AUTOSAR XML (schema 3.1.2)
package /Components/SWC_TraBVx
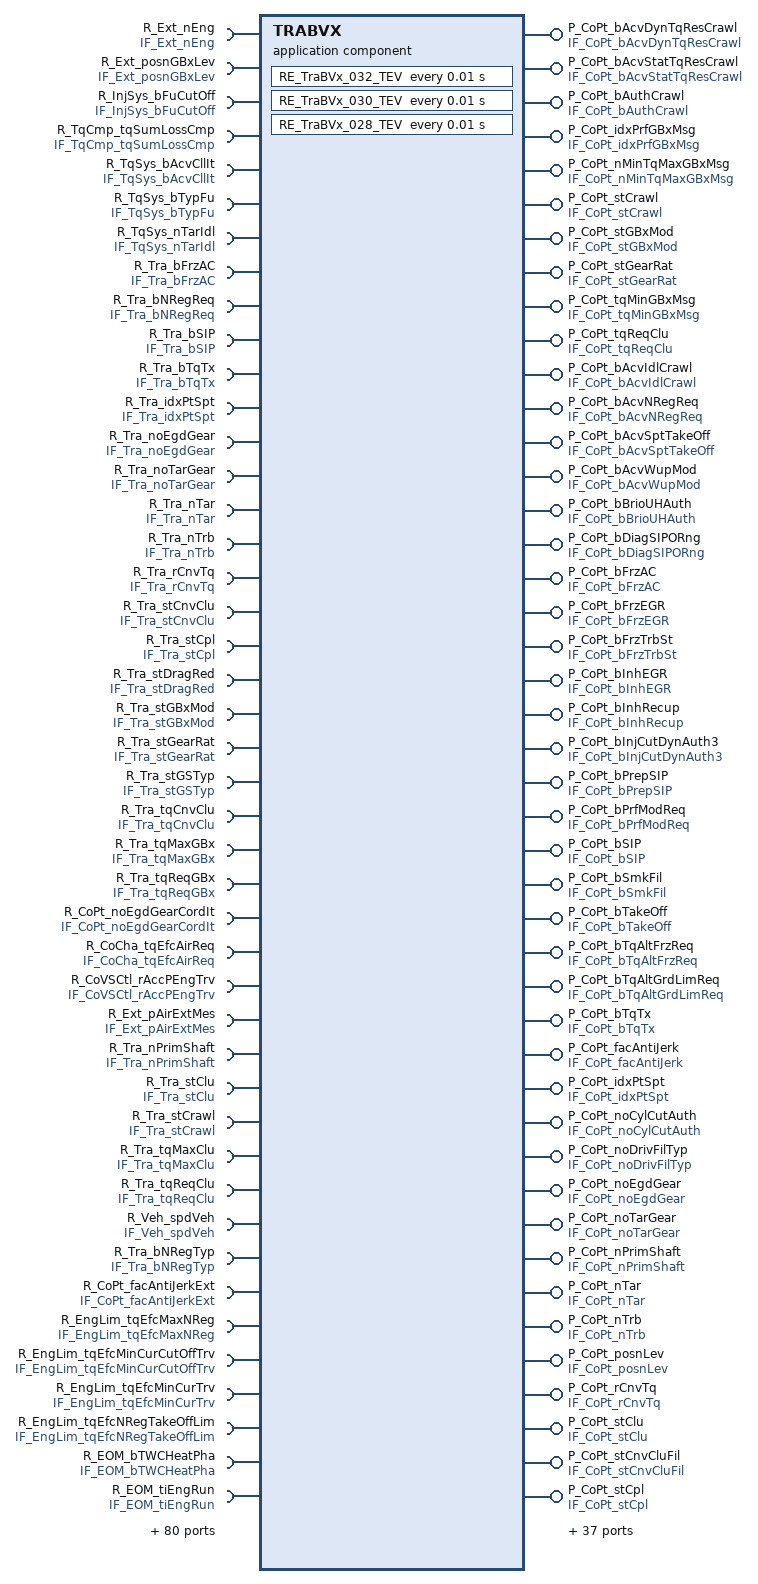
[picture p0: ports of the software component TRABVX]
  application software component type TRABVX
    124 x require port:
      R_Ext_nEng: unqueued-receiver-com-spec{data-element=Ext_nEng, init-value=ConstantValue, resync-time=0}, required-interface=IF_Ext_nEng  # Receiver of interface IF_Ext_nEng - Requirement Reference: [01552_10_01264-TraBVx-I038(0)]
      R_Ext_posnGBxLev: unqueued-receiver-com-spec{data-element=Ext_posnGBxLev, init-value=ConstantValue1, resync-time=0}, required-interface=IF_Ext_posnGBxLev  # Receiver of interface IF_Ext_posnGBxLev - Requirement Reference: [01552_10_01264-TraBVx-I039(0)]
      R_InjSys_bFuCutOff: unqueued-receiver-com-spec{data-element=InjSys_bFuCutOff, init-value=ConstantValue3, resync-time=0}, required-interface=IF_InjSys_bFuCutOff  # Receiver of interface IF_InjSys_bFuCutOff - Requirement Reference: [01552_10_01264-TraBVx-I040(1)]
      R_TqCmp_tqSumLossCmp: unqueued-receiver-com-spec{data-element=TqCmp_tqSumLossCmp, init-value=ConstantValue5, resync-time=0}, required-interface=IF_TqCmp_tqSumLossCmp  # Receiver of interface IF_TqCmp_tqSumLossCmp - Requirement Reference: [01552_10_01264-TraBVx-I041(0)]
      R_TqSys_bAcvCllIt: unqueued-receiver-com-spec{data-element=TqSys_bAcvCllIt, init-value=ConstantValue7, resync-time=0}, required-interface=IF_TqSys_bAcvCllIt  # Receiver of interface IF_TqSys_bAcvCllIt - Requirement Reference: [01552_10_01264-TraBVx-I042(0)]
      R_TqSys_bTypFu: unqueued-receiver-com-spec{data-element=TqSys_bTypFu, init-value=ConstantValue9, resync-time=0}, required-interface=IF_TqSys_bTypFu  # Receiver of interface IF_TqSys_bTypFu - Requirement Reference: [01552_10_01264-TraBVx-I043(0)]
      R_TqSys_nTarIdl: unqueued-receiver-com-spec{data-element=TqSys_nTarIdl, init-value=ConstantValue11, resync-time=0}, required-interface=IF_TqSys_nTarIdl  # Receiver of interface IF_TqSys_nTarIdl - Requirement Reference: [01552_10_01264-TraBVx-I044(0)]
      R_Tra_bFrzAC: unqueued-receiver-com-spec{data-element=Tra_bFrzAC, init-value=Tra_bFrzAC_Cst, resync-time=0}, required-interface=IF_Tra_bFrzAC  # Receiver of interface IF_Tra_bFrzAC - Requirement Reference: [01552_10_01264-TraBVx-I046(0)]
      R_Tra_bNRegReq: unqueued-receiver-com-spec{data-element=Tra_bNRegReq, init-value=Tra_bNRegReq_Cst, resync-time=0}, required-interface=IF_Tra_bNRegReq  # Receiver of interface IF_Tra_bNRegReq - Requirement Reference: [01552_10_01264-TraBVx-I047(0)]
      R_Tra_bSIP: unqueued-receiver-com-spec{data-element=Tra_bSIP, init-value=Tra_bSIP_Cst, resync-time=0}, required-interface=IF_Tra_bSIP  # Receiver of interface IF_Tra_bSIP - Requirement Reference: [01552_10_01264-TraBVx-I049(0)]
      R_Tra_bTqTx: unqueued-receiver-com-spec{data-element=Tra_bTqTx, init-value=Tra_bTqTx_Cst, resync-time=0}, required-interface=IF_Tra_bTqTx  # Receiver of interface IF_Tra_bTqTx - Requirement Reference: [01552_10_01264-TraBVx-I050(1)]
      R_Tra_idxPtSpt: unqueued-receiver-com-spec{data-element=Tra_idxPtSpt, init-value=Tra_idxPtSpt_Cst, resync-time=0}, required-interface=IF_Tra_idxPtSpt  # Receiver of interface IF_Tra_idxPtSpt - Requirement Reference: [01552_10_01264-TraBVx-I051(1)]
      R_Tra_noEgdGear: unqueued-receiver-com-spec{data-element=Tra_noEgdGear, init-value=ConstantValue13, resync-time=0}, required-interface=IF_Tra_noEgdGear  # Receiver of interface IF_Tra_noEgdGear - Requirement Reference: [01552_10_01264-TraBVx-I052(2)]
      R_Tra_noTarGear: unqueued-receiver-com-spec{data-element=Tra_noTarGear, init-value=ConstantValue15, resync-time=0}, required-interface=IF_Tra_noTarGear  # Receiver of interface IF_Tra_noTarGear - Requirement Reference: [01552_10_01264-TraBVx-I053(2)]
      R_Tra_nTar: unqueued-receiver-com-spec{data-element=Tra_nTar, init-value=Tra_nTar_Cst, resync-time=0}, required-interface=IF_Tra_nTar  # Receiver of interface IF_Tra_nTar - Requirement Reference: [01552_10_01264-TraBVx-I054(0)]
      R_Tra_nTrb: unqueued-receiver-com-spec{data-element=Tra_nTrb, init-value=Tra_nTrb_Cst, resync-time=0}, required-interface=IF_Tra_nTrb  # Receiver of interface IF_Tra_nTrb - Requirement Reference: [01552_10_01264-TraBVx-I055(1)]
      R_Tra_rCnvTq: unqueued-receiver-com-spec{data-element=Tra_rCnvTq, init-value=Tra_rCnvTq_Cst, resync-time=0}, required-interface=IF_Tra_rCnvTq  # Receiver of interface IF_Tra_rCnvTq - Requirement Reference: [01552_10_01264-TraBVx-I056(1)]
      R_Tra_stCnvClu: unqueued-receiver-com-spec{data-element=Tra_stCnvClu, init-value=Tra_stCnvClu_Cst, resync-time=0}, required-interface=IF_Tra_stCnvClu  # Receiver of interface IF_Tra_stCnvClu - Requirement Reference: [01552_10_01264-TraBVx-I057(0)]
      R_Tra_stCpl: unqueued-receiver-com-spec{data-element=Tra_stCpl, init-value=Tra_stCpl_Cst, resync-time=0}, required-interface=IF_Tra_stCpl  # Receiver of interface IF_Tra_stCpl - Requirement Reference: [01552_10_01264-TraBVx-I058(1)]
      R_Tra_stDragRed: unqueued-receiver-com-spec{data-element=Tra_stDragRed, init-value=Tra_stDragRed_Cst, resync-time=0}, required-interface=IF_Tra_stDragRed  # Receiver of interface IF_Tra_stDragRed - Requirement Reference: [01552_10_01264-TraBVx-I059(0)]
      R_Tra_stGBxMod: unqueued-receiver-com-spec{data-element=Tra_stGBxMod, init-value=ConstantValue17, resync-time=0}, required-interface=IF_Tra_stGBxMod  # Receiver of interface IF_Tra_stGBxMod - Requirement Reference: [01552_10_01264-TraBVx-I060(1)]
      R_Tra_stGearRat: unqueued-receiver-com-spec{data-element=Tra_stGearRat, init-value=Tra_stGearRat_Cst, resync-time=0}, required-interface=IF_Tra_stGearRat  # Receiver of interface IF_Tra_stGearRat - Requirement Reference: [01552_10_01264-TraBVx-I061(1)]
      R_Tra_stGSTyp: unqueued-receiver-com-spec{data-element=Tra_stGSTyp, init-value=Tra_stGSTyp_Cst, resync-time=0}, required-interface=IF_Tra_stGSTyp  # Receiver of interface IF_Tra_stGSTyp - Requirement Reference: [01552_10_01264-TraBVx-I062(1)]
      R_Tra_tqCnvClu: unqueued-receiver-com-spec{data-element=Tra_tqCnvClu, init-value=Tra_tqCnvClu_Cst, resync-time=0}, required-interface=IF_Tra_tqCnvClu  # Receiver of interface IF_Tra_tqCnvClu - Requirement Reference: [01552_10_01264-TraBVx-I064(0)]
      R_Tra_tqMaxGBx: unqueued-receiver-com-spec{data-element=Tra_tqMaxGBx, init-value=Tra_tqMaxGBx_Cst, resync-time=0}, required-interface=IF_Tra_tqMaxGBx  # Receiver of interface IF_Tra_tqMaxGBx - Requirement Reference: [01552_10_01264-TraBVx-I065(0)]
      R_Tra_tqReqGBx: unqueued-receiver-com-spec{data-element=Tra_tqReqGBx, init-value=Tra_tqReqGBx_Cst, resync-time=0}, required-interface=IF_Tra_tqReqGBx  # Receiver of interface IF_Tra_tqReqGBx - Requirement Reference: [01552_10_01264-TraBVx-I066(0)]
      R_CoPt_noEgdGearCordIt: unqueued-receiver-com-spec{data-element=CoPt_noEgdGearCordIt, init-value=ConstantValue19, resync-time=0}, required-interface=IF_CoPt_noEgdGearCordIt  # Receiver of interface IF_CoPt_noEgdGearCordIt - Requirement Reference: [01552_10_01264-TraBVx-I104(0)]
      R_CoCha_tqEfcAirReq: unqueued-receiver-com-spec{data-element=CoCha_tqEfcAirReq, init-value=ConstantValue21, resync-time=0}, required-interface=IF_CoCha_tqEfcAirReq  # Receiver of interface IF_CoCha_tqEfcAirReq - Requirement Reference: [01552_10_01264-TraBVx-I143(1)]
      R_CoVSCtl_rAccPEngTrv: unqueued-receiver-com-spec{data-element=CoVSCtl_rAccPEngTrv, init-value=ConstantValue23, resync-time=0}, required-interface=IF_CoVSCtl_rAccPEngTrv  # Receiver of interface IF_CoVSCtl_rAccPEngTrv - Requirement Reference: [01552_10_01264-TraBVx-I144(1)]
      R_Ext_pAirExtMes: unqueued-receiver-com-spec{data-element=Ext_pAirExtMes, init-value=ConstantValue25, resync-time=0}, required-interface=IF_Ext_pAirExtMes  # Receiver of interface IF_Ext_pAirExtMes - Requirement Reference: [01552_10_01264-TraBVx-I145(0)]
      R_Tra_nPrimShaft: unqueued-receiver-com-spec{data-element=Tra_nPrimShaft, init-value=Tra_nPrimShaft_Cst, resync-time=0}, required-interface=IF_Tra_nPrimShaft  # Receiver of interface IF_Tra_nPrimShaft - Requirement Reference: [01552_10_01264-TraBVx-I147(0)]
      R_Tra_stClu: unqueued-receiver-com-spec{data-element=Tra_stClu, init-value=Tra_stClu_Cst, resync-time=0}, required-interface=IF_Tra_stClu  # Receiver of interface IF_Tra_stClu - Requirement Reference: [01552_10_01264-TraBVx-I148(0)]
      R_Tra_stCrawl: unqueued-receiver-com-spec{data-element=Tra_stCrawl, init-value=Tra_stCrawl_Cst, resync-time=0}, required-interface=IF_Tra_stCrawl  # Receiver of interface IF_Tra_stCrawl - Requirement Reference: [01552_10_01264-TraBVx-I149(1)]
      R_Tra_tqMaxClu: unqueued-receiver-com-spec{data-element=Tra_tqMaxClu, init-value=Tra_tqMaxClu_Cst, resync-time=0}, required-interface=IF_Tra_tqMaxClu  # Receiver of interface IF_Tra_tqMaxClu - Requirement Reference: [01552_10_01264-TraBVx-I151(0)]
      R_Tra_tqReqClu: unqueued-receiver-com-spec{data-element=Tra_tqReqClu, init-value=Tra_tqReqClu_Cst, resync-time=0}, required-interface=IF_Tra_tqReqClu  # Receiver of interface IF_Tra_tqReqClu - Requirement Reference: [01552_10_01264-TraBVx-I152(1)]
      R_Veh_spdVeh: unqueued-receiver-com-spec{data-element=Veh_spdVeh, init-value=ConstantValue27, resync-time=0}, required-interface=IF_Veh_spdVeh  # Receiver of interface IF_Veh_spdVeh - Requirement Reference: [01552_10_01264-TraBVx-I153(0)]
      R_Tra_bNRegTyp: unqueued-receiver-com-spec{data-element=Tra_bNRegTyp, init-value=Tra_bNRegTyp_Cst, resync-time=0}, required-interface=IF_Tra_bNRegTyp  # Receiver of interface IF_Tra_bNRegTyp - Requirement Reference: [01552_10_01264-TraBVx-I192(1)]
      R_CoPt_facAntiJerkExt: unqueued-receiver-com-spec{data-element=CoPt_facAntiJerkExt, init-value=CoPt_facAntiJerkExt_Cst, resync-time=0}, required-interface=IF_CoPt_facAntiJerkExt  # Receiver of interface IF_CoPt_facAntiJerkExt - Requirement Reference: [01552_10_01264-TraBVx-I287(1)]
      R_EngLim_tqEfcMaxNReg: unqueued-receiver-com-spec{data-element=EngLim_tqEfcMaxNReg, init-value=ConstantValue29, resync-time=0}, required-interface=IF_EngLim_tqEfcMaxNReg  # Receiver of interface IF_EngLim_tqEfcMaxNReg - Requirement Reference: [01552_10_01264-TraBVx-I404(1)]
      R_EngLim_tqEfcMinCurCutOffTrv: unqueued-receiver-com-spec{data-element=EngLim_tqEfcMinCurCutOffTrv, init-value=ConstantValue31, resync-time=0}, required-interface=IF_EngLim_tqEfcMinCurCutOffTrv  # Receiver of interface IF_EngLim_tqEfcMinCurCutOffTrv - Requirement Reference: [01552_10_01264-TraBVx-I405(1)]
      R_EngLim_tqEfcMinCurTrv: unqueued-receiver-com-spec{data-element=EngLim_tqEfcMinCurTrv, init-value=ConstantValue33, resync-time=0}, required-interface=IF_EngLim_tqEfcMinCurTrv  # Receiver of interface IF_EngLim_tqEfcMinCurTrv - Requirement Reference: [01552_10_01264-TraBVx-I406(1)]
      R_EngLim_tqEfcNRegTakeOffLim: unqueued-receiver-com-spec{data-element=EngLim_tqEfcNRegTakeOffLim, init-value=ConstantValue35, resync-time=0}, required-interface=IF_EngLim_tqEfcNRegTakeOffLim  # Receiver of interface IF_EngLim_tqEfcNRegTakeOffLim - Requirement Reference: [01552_10_01264-TraBVx-I407(0)]
      R_EOM_bTWCHeatPha: unqueued-receiver-com-spec{data-element=EOM_bTWCHeatPha, init-value=ConstantValue37, resync-time=0}, required-interface=IF_EOM_bTWCHeatPha  # Receiver of interface IF_EOM_bTWCHeatPha - Requirement Reference: [01552_10_01264-TraBVx-I408(1)]
      R_EOM_tiEngRun: unqueued-receiver-com-spec{data-element=EOM_tiEngRun, init-value=ConstantValue39, resync-time=0}, required-interface=IF_EOM_tiEngRun  # Receiver of interface IF_EOM_tiEngRun - Requirement Reference: [01552_10_01264-TraBVx-I409(0)]
      R_Ext_stGBxCf: unqueued-receiver-com-spec{data-element=Ext_stGBxCf, init-value=ConstantValue41, resync-time=0}, required-interface=IF_Ext_stGBxCf  # Receiver of interface IF_Ext_stGBxCf - Requirement Reference: [01552_10_01264-TraBVx-I410(0)]
      R_Ext_stTraTypCf: unqueued-receiver-com-spec{data-element=Ext_stTraTypCf, init-value=ConstantValue43, resync-time=0}, required-interface=IF_Ext_stTraTypCf  # Receiver of interface IF_Ext_stTraTypCf - Requirement Reference: [01552_10_01264-TraBVx-I411(1)]
      R_Ext_tAir: unqueued-receiver-com-spec{data-element=Ext_tAir, init-value=ConstantValue45, resync-time=0}, required-interface=IF_Ext_tAir  # Receiver of interface IF_Ext_tAir - Requirement Reference: [01552_10_01264-TraBVx-I412(0)]
      R_Ext_tCoMes: unqueued-receiver-com-spec{data-element=Ext_tCoMes, init-value=ConstantValue47, resync-time=0}, required-interface=IF_Ext_tCoMes  # Receiver of interface IF_Ext_tCoMes - Requirement Reference: [01552_10_01264-TraBVx-I413(1)]
      R_TqSys_bAcvOvbReq: unqueued-receiver-com-spec{data-element=TqSys_bAcvOvbReq, init-value=TqSys_bAcvOvbReq_Cst, resync-time=0}, required-interface=IF_TqSys_bAcvOvbReq  # Receiver of interface IF_TqSys_bAcvOvbReq - Requirement Reference: [01552_10_01264-TraBVx-I414(1)]
      R_TqSys_stTypPwtCf: unqueued-receiver-com-spec{data-element=TqSys_stTypPwtCf, init-value=ConstantValue49, resync-time=0}, required-interface=IF_TqSys_stTypPwtCf  # Receiver of interface IF_TqSys_stTypPwtCf - Requirement Reference: [01552_10_01264-TraBVx-I416(0)]
      R_TqSys_tiDeacOvbReq: unqueued-receiver-com-spec{data-element=TqSys_tiDeacOvbReq, init-value=TqSys_tiDeacOvbReq_Cst, resync-time=0}, required-interface=IF_TqSys_tiDeacOvbReq  # Receiver of interface IF_TqSys_tiDeacOvbReq - Requirement Reference: [01552_10_01264-TraBVx-I417(1)]
      R_TqSys_tqEfcIdl: unqueued-receiver-com-spec{data-element=TqSys_tqEfcIdl, init-value=ConstantValue51, resync-time=0}, required-interface=IF_TqSys_tqEfcIdl  # Receiver of interface IF_TqSys_tqEfcIdl - Requirement Reference: [01552_10_01264-TraBVx-I418(1)]
      R_Cha_tqDynASRReq: unqueued-receiver-com-spec{data-element=Cha_tqDynASRReq, init-value=ConstantValue53, resync-time=0}, required-interface=IF_Cha_tqDynASRReq  # Receiver of interface IF_Cha_tqDynASRReq - Requirement Reference: [01552_10_01264-TraBVx-I423(0)]
      R_Cha_tqMSRReq: unqueued-receiver-com-spec{data-element=Cha_tqMSRReq, init-value=ConstantValue55, resync-time=0}, required-interface=IF_Cha_tqMSRReq  # Receiver of interface IF_Cha_tqMSRReq - Requirement Reference: [01552_10_01264-TraBVx-I424(0)]
      R_CoCha_tqEfcReq: unqueued-receiver-com-spec{data-element=CoCha_tqEfcReq, init-value=ConstantValue57, resync-time=0}, required-interface=IF_CoCha_tqEfcReq  # Receiver of interface IF_CoCha_tqEfcReq - Requirement Reference: [01552_10_01264-TraBVx-I425(0)]
      R_CoCha_tqEfcReqExt: unqueued-receiver-com-spec{data-element=CoCha_tqEfcReqExt, init-value=CoCha_tqEfcReqExt_Cst, resync-time=0}, required-interface=IF_CoCha_tqEfcReqExt  # Receiver of interface IF_CoCha_tqEfcReqExt - Requirement Reference: [01552_10_01264-TraBVx-I426(1)]
      R_CoPt_bAcvTqMaxEstim: unqueued-receiver-com-spec{data-element=CoPt_bAcvTqMaxEstim, init-value=CoPt_bAcvTqMaxEstim_Cst, resync-time=0}, required-interface=IF_CoPt_bAcvTqMaxEstim  # Receiver of interface IF_CoPt_bAcvTqMaxEstim - Requirement Reference: [01552_10_01264-TraBVx-I427(1)]
      R_CoPt_bSIP: unqueued-receiver-com-spec{data-element=CoPt_bSIP, init-value=ConstantValue59, resync-time=0}, required-interface=IF_CoPt_bSIP  # Receiver of interface IF_CoPt_bSIP - Requirement Reference: [01552_10_01264-TraBVx-I428(1)]
      R_TqCmp_tqCnvLoss: unqueued-receiver-com-spec{data-element=TqCmp_tqCnvLoss, init-value=ConstantValue61, resync-time=0}, required-interface=IF_TqCmp_tqCnvLoss  # Receiver of interface IF_TqCmp_tqCnvLoss - Requirement Reference: [01552_10_01264-TraBVx-I432(0)]
      R_TqLimEM_tqLimEM: unqueued-receiver-com-spec{data-element=TqLimEM_tqLimEM, init-value=ConstantValue63, resync-time=0}, required-interface=IF_TqLimEM_tqLimEM  # Receiver of interface IF_TqLimEM_tqLimEM - Requirement Reference: [01552_10_01264-TraBVx-I433(0)]
      R_TqLimEM_tqLimEMExt: unqueued-receiver-com-spec{data-element=TqLimEM_tqLimEMExt, init-value=ConstantValue65, resync-time=0}, required-interface=IF_TqLimEM_tqLimEMExt  # Receiver of interface IF_TqLimEM_tqLimEMExt - Requirement Reference: [01552_10_01264-TraBVx-I434(1)]
      R_TqSys_tqCkEfcFil: unqueued-receiver-com-spec{data-element=TqSys_tqCkEfcFil, init-value=ConstantValue67, resync-time=0}, required-interface=IF_TqSys_tqCkEfcFil  # Receiver of interface IF_TqSys_tqCkEfcFil - Requirement Reference: [01552_10_01264-TraBVx-I436(0)]
      R_TqSys_tqCkEfcFilExt: unqueued-receiver-com-spec{data-element=TqSys_tqCkEfcFilExt, init-value=ConstantValue69, resync-time=0}, required-interface=IF_TqSys_tqCkEfcFilExt  # Receiver of interface IF_TqSys_tqCkEfcFilExt - Requirement Reference: [01552_10_01264-TraBVx-I437(1)]
      R_CoPt_bAcvNRegReqBuf: unqueued-receiver-com-spec{data-element=CoPt_bAcvNRegReqBuf, init-value=ConstantValue71, resync-time=0}, required-interface=IF_CoPt_bAcvNRegReqBuf  # Receiver of interface IF_CoPt_bAcvNRegReqBuf - Requirement Reference: [01552_10_01264-TraBVx-I440(0)]
      R_CoPt_noTarGearCordBuf: unqueued-receiver-com-spec{data-element=CoPt_noTarGearCordBuf, init-value=ConstantValue73, resync-time=0}, required-interface=IF_CoPt_noTarGearCordBuf  # Receiver of interface IF_CoPt_noTarGearCordBuf - Requirement Reference: [01552_10_01264-TraBVx-I441(0)]
      R_CoPt_noTarGearCordIt: unqueued-receiver-com-spec{data-element=CoPt_noTarGearCordIt, init-value=ConstantValue75, resync-time=0}, required-interface=IF_CoPt_noTarGearCordIt  # Receiver of interface IF_CoPt_noTarGearCordIt - Requirement Reference: [01552_10_01264-TraBVx-I442(0)]
      R_CoPt_nTar: unqueued-receiver-com-spec{data-element=CoPt_nTar, init-value=ConstantValue77, resync-time=0}, required-interface=IF_CoPt_nTar  # Receiver of interface IF_CoPt_nTar - Requirement Reference: [01552_10_01264-TraBVx-I444(1)]
      R_CoPt_nTarBuf: unqueued-receiver-com-spec{data-element=CoPt_nTarBuf, init-value=ConstantValue79, resync-time=0}, required-interface=IF_CoPt_nTarBuf  # Receiver of interface IF_CoPt_nTarBuf - Requirement Reference: [01552_10_01264-TraBVx-I445(0)]
      R_CoPt_tqIdcAirCordLim_tqGBx: unqueued-receiver-com-spec{data-element=CoPt_tqIdcAirCordLim_tqGBx, init-value=ConstantValue81, resync-time=0}, required-interface=IF_CoPt_tqIdcAirCordLim_tqGBx  # Receiver of interface IF_CoPt_tqIdcAirCordLim_tqGBx - Requirement Reference: [01552_10_01264-TraBVx-I447(1)]
      R_CoPt_tqMaxGBx_nRegBuf: unqueued-receiver-com-spec{data-element=CoPt_tqMaxGBx_nRegBuf, init-value=ConstantValue83, resync-time=0}, required-interface=IF_CoPt_tqMaxGBx_nRegBuf  # Receiver of interface IF_CoPt_tqMaxGBx_nRegBuf - Requirement Reference: [01552_10_01264-TraBVx-I448(0)]
      R_TqEst_tqIdcStrt: unqueued-receiver-com-spec{data-element=TqEst_tqIdcStrt, init-value=TqEst_tqIdcStrt_Cst, resync-time=0}, required-interface=IF_TqEst_tqIdcStrt  # Receiver of interface IF_TqEst_tqIdcStrt - Requirement Reference: [01552_10_01264-TraBVx-I449(0)]
      R_TqSys_bTqSysAcv: unqueued-receiver-com-spec{data-element=TqSys_bTqSysAcv, init-value=ConstantValue85, resync-time=0}, required-interface=IF_TqSys_bTqSysAcv  # Receiver of interface IF_TqSys_bTqSysAcv - Requirement Reference: [01552_10_01264-TraBVx-I450(0)]
      R_TqSys_EveSync_CoPtNReg: unqueued-receiver-com-spec{data-element=TqSys_EveSync_CoPtNReg, init-value=TqSys_EveSync_CoPtNReg_Cst, resync-time=0}, required-interface=IF_TqSys_EveSync_CoPtNReg  # Receiver of interface IF_TqSys_EveSync_CoPtNReg - Requirement Reference: [01552_10_01264-TraBVx-I451(0)]
      R_Cha_stTqReq: unqueued-receiver-com-spec{data-element=Cha_stTqReq, init-value=ConstantValue87, resync-time=0}, required-interface=IF_Cha_stTqReq  # Receiver of interface IF_Cha_stTqReq - Requirement Reference: [01552_10_01264-TraBVx-I457(0)]
      R_CoPt_bSIPBuf: unqueued-receiver-com-spec{data-element=CoPt_bSIPBuf, init-value=ConstantValue89, resync-time=0}, required-interface=IF_CoPt_bSIPBuf  # Receiver of interface IF_CoPt_bSIPBuf - Requirement Reference: [01552_10_01264-TraBVx-I458(0)]
      R_CoPt_tqIdcCordLimBuf_tqGBx: unqueued-receiver-com-spec{data-element=CoPt_tqIdcCordLimBuf_tqGBx, init-value=ConstantValue91, resync-time=0}, required-interface=IF_CoPt_tqIdcCordLimBuf_tqGBx  # Receiver of interface IF_CoPt_tqIdcCordLimBuf_tqGBx - Requirement Reference: [01552_10_01264-TraBVx-I459(0)]
      R_Ext_tiTDC: unqueued-receiver-com-spec{data-element=Ext_tiTDC, init-value=ConstantValue93, resync-time=0}, required-interface=IF_Ext_tiTDC  # Receiver of interface IF_Ext_tiTDC - Requirement Reference: [01552_10_01264-TraBVx-I461(0)]
      R_TqLimEM_tqIdcLimEM: unqueued-receiver-com-spec{data-element=TqLimEM_tqIdcLimEM, init-value=ConstantValue95, resync-time=0}, required-interface=IF_TqLimEM_tqIdcLimEM  # Receiver of interface IF_TqLimEM_tqIdcLimEM - Requirement Reference: [01552_10_01264-TraBVx-I462(1)]
      R_TqSys_bInjCutDynReq: unqueued-receiver-com-spec{data-element=TqSys_bInjCutDynReq, init-value=ConstantValue97, resync-time=0}, required-interface=IF_TqSys_bInjCutDynReq  # Receiver of interface IF_TqSys_bInjCutDynReq - Requirement Reference: [01552_10_01264-TraBVx-I463(0)]
      R_TqSys_EveSync_CoPtNRegCord: unqueued-receiver-com-spec{data-element=TqSys_EveSync_CoPtNRegCord, init-value=TqSys_EveSync_CoPtNRegCord_Cst, resync-time=0}, required-interface=IF_TqSys_EveSync_CoPtNRegCord  # Receiver of interface IF_TqSys_EveSync_CoPtNRegCord - Requirement Reference: [01552_10_01264-TraBVx-I464(0)]
      R_CoPt_bDeacCllBuf: unqueued-receiver-com-spec{data-element=CoPt_bDeacCllBuf, init-value=ConstantValue99, resync-time=0}, required-interface=IF_CoPt_bDeacCllBuf  # Receiver of interface IF_CoPt_bDeacCllBuf - Requirement Reference: [01552_10_01264-TraBVx-I471(0)]
      R_CoPt_bPrepSIP: unqueued-receiver-com-spec{data-element=CoPt_bPrepSIP, init-value=ConstantValue101, resync-time=0}, required-interface=IF_CoPt_bPrepSIP  # Receiver of interface IF_CoPt_bPrepSIP - Requirement Reference: [01552_10_01264-TraBVx-I474(1)]
      R_CoPt_nTrb: unqueued-receiver-com-spec{data-element=CoPt_nTrb, init-value=ConstantValue103, resync-time=0}, required-interface=IF_CoPt_nTrb  # Receiver of interface IF_CoPt_nTrb - Requirement Reference: [01552_10_01264-TraBVx-I475(1)]
      R_CoPt_tqDrvFil: unqueued-receiver-com-spec{data-element=CoPt_tqDrvFil, init-value=CoPt_tqDrvFil_Cst, resync-time=0}, required-interface=IF_CoPt_tqDrvFil  # Receiver of interface IF_CoPt_tqDrvFil - Requirement Reference: [01552_10_01264-TraBVx-I476(1)]
      R_CoPt_tqDrvRaw: unqueued-receiver-com-spec{data-element=CoPt_tqDrvRaw, init-value=CoPt_tqDrvRaw_Cst, resync-time=0}, required-interface=IF_CoPt_tqDrvRaw  # Receiver of interface IF_CoPt_tqDrvRaw - Requirement Reference: [01552_10_01264-TraBVx-I477(1)]
      R_CoPt_tqIdcCord_nRegReq: unqueued-receiver-com-spec{data-element=CoPt_tqIdcCord_nRegReq, init-value=CoPt_tqIdcCord_nRegReq_Cst, resync-time=0}, required-interface=IF_CoPt_tqIdcCord_nRegReq  # Receiver of interface IF_CoPt_tqIdcCord_nRegReq - Requirement Reference: [01552_10_01264-TraBVx-I478(1)]
      R_CoPt_tqIdcMaxGBxBuf: unqueued-receiver-com-spec{data-element=CoPt_tqIdcMaxGBxBuf, init-value=ConstantValue105, resync-time=0}, required-interface=IF_CoPt_tqIdcMaxGBxBuf  # Receiver of interface IF_CoPt_tqIdcMaxGBxBuf - Requirement Reference: [01552_10_01264-TraBVx-I479(0)]
      R_CoPt_tqMaxGBx: unqueued-receiver-com-spec{data-element=CoPt_tqMaxGBx, init-value=ConstantValue107, resync-time=0}, required-interface=IF_CoPt_tqMaxGBx  # Receiver of interface IF_CoPt_tqMaxGBx - Requirement Reference: [01552_10_01264-TraBVx-I480(1)]
      R_TqSys_EveSync_CoPtNCross: unqueued-receiver-com-spec{data-element=TqSys_EveSync_CoPtNCross, init-value=TqSys_EveSync_CoPtNCross_Cst, resync-time=0}, required-interface=IF_TqSys_EveSync_CoPtNCross  # Receiver of interface IF_TqSys_EveSync_CoPtNCross - Requirement Reference: [01552_10_01264-TraBVx-I481(0)]
      R_TqSys_idxTqAccu: unqueued-receiver-com-spec{data-element=TqSys_idxTqAccu, init-value=ConstantValue109, resync-time=0}, required-interface=IF_TqSys_idxTqAccu  # Receiver of interface IF_TqSys_idxTqAccu - Requirement Reference: [01552_10_01264-TraBVx-I482(0)]
      R_TreatTDC_nCkGrd: unqueued-receiver-com-spec{data-element=TreatTDC_nCkGrd, init-value=ConstantValue111, resync-time=0}, required-interface=IF_TreatTDC_nCkGrd  # Receiver of interface IF_TreatTDC_nCkGrd - Requirement Reference: [01552_10_01264-TraBVx-I483(0)]
      R_CoCha_tqEfcAirReqExt: unqueued-receiver-com-spec{data-element=CoCha_tqEfcAirReqExt, init-value=CoCha_tqEfcAirReqExt_Cst, resync-time=0}, required-interface=IF_CoCha_tqEfcAirReqExt  # Receiver of interface IF_CoCha_tqEfcAirReqExt - Requirement Reference: [01552_10_01264-TraBVx-I486(1)]
      R_TqCha_tqAirTqDecReq: unqueued-receiver-com-spec{data-element=TqCha_tqAirTqDecReq, init-value=ConstantValue113, resync-time=0}, required-interface=IF_TqCha_tqAirTqDecReq  # Receiver of interface IF_TqCha_tqAirTqDecReq - Requirement Reference: [01552_10_01264-TraBVx-I488(1)]
      R_TqCha_tqAirTqDecReqExt: unqueued-receiver-com-spec{data-element=TqCha_tqAirTqDecReqExt, init-value=TqCha_tqAirTqDecReqExt_Cst, resync-time=0}, required-interface=IF_TqCha_tqAirTqDecReqExt  # Receiver of interface IF_TqCha_tqAirTqDecReqExt - Requirement Reference: [01552_10_01264-TraBVx-I489(1)]
      R_TqCha_tqAirTqIncReq: unqueued-receiver-com-spec{data-element=TqCha_tqAirTqIncReq, init-value=ConstantValue115, resync-time=0}, required-interface=IF_TqCha_tqAirTqIncReq  # Receiver of interface IF_TqCha_tqAirTqIncReq - Requirement Reference: [01552_10_01264-TraBVx-I490(1)]
      R_TqCha_tqAirTqIncReqExt: unqueued-receiver-com-spec{data-element=TqCha_tqAirTqIncReqExt, init-value=TqCha_tqAirTqIncReqExt_Cst, resync-time=0}, required-interface=IF_TqCha_tqAirTqIncReqExt  # Receiver of interface IF_TqCha_tqAirTqIncReqExt - Requirement Reference: [01552_10_01264-TraBVx-I491(1)]
      R_TqSys_tqCkEfcAirFil: unqueued-receiver-com-spec{data-element=TqSys_tqCkEfcAirFil, init-value=ConstantValue117, resync-time=0}, required-interface=IF_TqSys_tqCkEfcAirFil  # Receiver of interface IF_TqSys_tqCkEfcAirFil - Requirement Reference: [01552_10_01264-TraBVx-I493(1)]
      R_TqSys_tqCkEfcAirFilExt: unqueued-receiver-com-spec{data-element=TqSys_tqCkEfcAirFilExt, init-value=TqSys_tqCkEfcAirFilExt_Cst, resync-time=0}, required-interface=IF_TqSys_tqCkEfcAirFilExt  # Receiver of interface IF_TqSys_tqCkEfcAirFilExt - Requirement Reference: [01552_10_01264-TraBVx-I494(1)]
      R_TqSys_tqEfcAirIdl: unqueued-receiver-com-spec{data-element=TqSys_tqEfcAirIdl, init-value=ConstantValue119, resync-time=0}, required-interface=IF_TqSys_tqEfcAirIdl  # Receiver of interface IF_TqSys_tqEfcAirIdl - Requirement Reference: [01552_10_01264-TraBVx-I495(1)]
      R_CoPt_bAcvNRegReq: unqueued-receiver-com-spec{data-element=CoPt_bAcvNRegReq, init-value=ConstantValue121, resync-time=0}, required-interface=IF_CoPt_bAcvNRegReq  # Receiver of interface IF_CoPt_bAcvNRegReq - Requirement Reference: [01552_10_01264-TraBVx-I497(1)]
      R_CoPt_bAcvNCross: unqueued-receiver-com-spec{data-element=CoPt_bAcvNCross, init-value=CoPt_bAcvNCross_Cst, resync-time=0}, required-interface=IF_CoPt_bAcvNCross  # Receiver of interface IF_CoPt_bAcvNCross - Requirement Reference: [01552_10_01264-TraBVx-I501(1)]
      R_CoPt_tqIdcAirMaxGBx: unqueued-receiver-com-spec{data-element=CoPt_tqIdcAirMaxGBx, init-value=ConstantValue123, resync-time=0}, required-interface=IF_CoPt_tqIdcAirMaxGBx  # Receiver of interface IF_CoPt_tqIdcAirMaxGBx - Requirement Reference: [01552_10_01264-TraBVx-I503(1)]
      R_CoPtUH_bRStrtTypAT: unqueued-receiver-com-spec{data-element=CoPtUH_bRStrtTypAT, init-value=ConstantValue125, resync-time=0}, required-interface=IF_CoPtUH_bRStrtTypAT  # Receiver of interface IF_CoPtUH_bRStrtTypAT - Requirement Reference: [01552_10_01264-TraBVx-I504(0)]
      R_Tra_bSIPPrep: unqueued-receiver-com-spec{data-element=Tra_bSIPPrep, init-value=Tra_bSIPPrep_Cst, resync-time=0}, required-interface=IF_Tra_bSIPPrep  # Receiver of interface IF_Tra_bSIPPrep - Requirement Reference: [01552_10_01264-TraBVx-I505(0)]
      R_Tra_stPhaGearShift: unqueued-receiver-com-spec{data-element=Tra_stPhaGearShift, init-value=Tra_stPhaGearShift_Cst, resync-time=0}, required-interface=IF_Tra_stPhaGearShift  # Receiver of interface IF_Tra_stPhaGearShift - Requirement Reference: [01552_10_01264-TraBVx-I506(0)]
      R_TqSys_stStrtEngTyp: unqueued-receiver-com-spec{data-element=TqSys_stStrtEngTyp, init-value=TqSys_stStrtEngTyp_Cst, resync-time=0}, required-interface=IF_TqSys_stStrtEngTyp  # Receiver of interface IF_TqSys_stStrtEngTyp - Requirement Reference: [01552_10_01264-TraBVx-I507(0)]
      R_Ext_tOilGBx: unqueued-receiver-com-spec{data-element=Ext_tOilGBx, init-value=ConstantValue127, resync-time=0}, required-interface=IF_Ext_tOilGBx  # Receiver of interface IF_Ext_tOilGBx - Requirement Reference: [01552_10_01264-TraBVx-I508(1)]
      R_Tra_bVoltAltBoostReqGBx: unqueued-receiver-com-spec{data-element=Tra_bVoltAltBoostReqGBx, init-value=Tra_bVoltAltBoostReqGBx_Cst, resync-time=0}, required-interface=IF_Tra_bVoltAltBoostReqGBx  # Receiver of interface IF_Tra_bVoltAltBoostReqGBx - Requirement Reference: [01552_10_01264-TraBVx-I678(0)]
      R_Ext_dstVehTotMes: unqueued-receiver-com-spec{data-element=Ext_dstVehTotMes, init-value=ConstantValue129, resync-time=0}, required-interface=IF_Ext_dstVehTotMes  # Receiver of interface IF_Ext_dstVehTotMes - Requirement Reference: [01552_10_01264-TraBVx-I679(0)]
      R_CoPt_bAcvTqNCordBuf: unqueued-receiver-com-spec{data-element=CoPt_bAcvTqNCordBuf, init-value=CoPt_bAcvTqNCordBuf_Cst, resync-time=0}, required-interface=IF_CoPt_bAcvTqNCordBuf  # Receiver of interface IF_CoPt_bAcvTqNCordBuf - Requirement Reference: [01552_10_01264-TraBVx-I680(0)]
      R_CoVSCtl_tqIdcSIPTar: unqueued-receiver-com-spec{data-element=CoVSCtl_tqIdcSIPTar, init-value=CoVSCtl_tqIdcSIPTar_Cst, resync-time=0}, required-interface=IF_CoVSCtl_tqIdcSIPTar  # Receiver of interface IF_CoVSCtl_tqIdcSIPTar - Requirement Reference: [01552_10_01264-TraBVx-I681(0)]
      R_CoVSCtl_tqSIPTar: unqueued-receiver-com-spec{data-element=CoVSCtl_tqSIPTar, init-value=CoVSCtl_tqSIPTar_Cst, resync-time=0}, required-interface=IF_CoVSCtl_tqSIPTar  # Receiver of interface IF_CoVSCtl_tqSIPTar - Requirement Reference: [01552_10_01264-TraBVx-I683(0)]
      R_CoPt_bAcvTqNCord: unqueued-receiver-com-spec{data-element=CoPt_bAcvTqNCord, init-value=CoPt_bAcvTqNCord_Cst, resync-time=0}, required-interface=IF_CoPt_bAcvTqNCord  # Receiver of interface IF_CoPt_bAcvTqNCord - Requirement Reference: [01552_10_01264-TraBVx-I684(0)]
      R_Tra_bEngCrawlAuth: unqueued-receiver-com-spec{data-element=Tra_bEngCrawlAuth, init-value=Tra_bEngCrawlAuth_Cst, resync-time=0}, required-interface=IF_Tra_bEngCrawlAuth  # Receiver of interface IF_Tra_bEngCrawlAuth - Requirement Reference: [01552_10_01264-TraBVx-I685(0)]
      R_Tra_bSpdVehLoDet: unqueued-receiver-com-spec{data-element=Tra_bSpdVehLoDet, init-value=Tra_bSpdVehLoDet_Cst, resync-time=0}, required-interface=IF_Tra_bSpdVehLoDet  # Receiver of interface IF_Tra_bSpdVehLoDet - Requirement Reference: [01552_10_01264-TraBVx-I686(0)]
      R_Tra_stVehDirEstim: unqueued-receiver-com-spec{data-element=Tra_stVehDirEstim, init-value=Tra_stVehDirEstim_Cst, resync-time=0}, required-interface=IF_Tra_stVehDirEstim  # Receiver of interface IF_Tra_stVehDirEstim - Requirement Reference: [01552_10_01264-TraBVx-I687(0)]
      R_CoPt_tqFfNRegBuf: unqueued-receiver-com-spec{data-element=CoPt_tqFfNRegBuf, init-value=CoPt_tqFfNRegBuf_Cst, resync-time=0}, required-interface=IF_CoPt_tqFfNRegBuf  # Receiver of interface IF_CoPt_tqFfNRegBuf - Requirement Reference: [01552_10_01264-TraBVx-I688(0)]
      R_Tra_bInhAC: unqueued-receiver-com-spec{data-element=Tra_bInhAC, init-value=Tra_bInhAC_Cst, resync-time=0}, required-interface=IF_Tra_bInhAC  # Receiver of interface IF_Tra_bInhAC - Requirement Reference: [01552_10_01264-TraBVx-I691(0)]
      R_EngLim_tqCkEfcATLimCordEL2: unqueued-receiver-com-spec{data-element=EngLim_tqCkEfcATLimCordEL2, init-value=EngLim_tqCkEfcATLimCordEL2_Cst, resync-time=0}, required-interface=IF_EngLim_tqCkEfcATLimCordEL2  # Receiver of interface IF_EngLim_tqCkEfcATLimCordEL2 - Requirement Reference: [01552_10_01264-TraBVx-I696(0)]
      R_EngLim_tqCkEfcGBxLimCordEL2: unqueued-receiver-com-spec{data-element=EngLim_tqCkEfcGBxLimCordEL2, init-value=EngLim_tqCkEfcGBxLimCordEL2_Cst, resync-time=0}, required-interface=IF_EngLim_tqCkEfcGBxLimCordEL2  # Receiver of interface IF_EngLim_tqCkEfcGBxLimCordEL2 - Requirement Reference: [01552_10_01264-TraBVx-I697(0)]
      R_EcuM_CurrentMode: required-interface=EcuM_CurrentMode
      R_UCE_stWkuMainRelSt: required-interface=IF_UCE_stWkuMainRelSt
      R_FRM_bInhCoPtSIP: required-interface=FunctionInhibition  # 01552_10_01264-TraBVx-I507(0)
      R_FRM_bInhCoPtCrawl: required-interface=FunctionInhibition  # 01552_10_01264-TraBVx-I508(0)
    81 x provide port:
      P_CoPt_bAcvDynTqResCrawl: unqueued-sender-com-spec{data-element=CoPt_bAcvDynTqResCrawl, can-invalidate=false, init-value=CoPt_bAcvDynTqResCrawl_Cst}, provided-interface=IF_CoPt_bAcvDynTqResCrawl
      P_CoPt_bAcvStatTqResCrawl: unqueued-sender-com-spec{data-element=CoPt_bAcvStatTqResCrawl, can-invalidate=false, init-value=CoPt_bAcvStatTqResCrawl_Cst}, provided-interface=IF_CoPt_bAcvStatTqResCrawl
      P_CoPt_bAuthCrawl: unqueued-sender-com-spec{data-element=CoPt_bAuthCrawl, can-invalidate=false, init-value=CoPt_bAuthCrawl_Cst}, provided-interface=IF_CoPt_bAuthCrawl
      P_CoPt_idxPrfGBxMsg: unqueued-sender-com-spec{data-element=CoPt_idxPrfGBxMsg, can-invalidate=false, init-value=CoPt_idxPrfGBxMsg_Cst}, provided-interface=IF_CoPt_idxPrfGBxMsg
      P_CoPt_nMinTqMaxGBxMsg: unqueued-sender-com-spec{data-element=CoPt_nMinTqMaxGBxMsg, can-invalidate=false, init-value=CoPt_nMinTqMaxGBxMsg_Cst}, provided-interface=IF_CoPt_nMinTqMaxGBxMsg
      P_CoPt_stCrawl: unqueued-sender-com-spec{data-element=CoPt_stCrawl, can-invalidate=false, init-value=CoPt_stCrawl_Cst}, provided-interface=IF_CoPt_stCrawl
      P_CoPt_stGBxMod: unqueued-sender-com-spec{data-element=CoPt_stGBxMod, can-invalidate=false, init-value=CoPt_stGBxMod_Cst}, provided-interface=IF_CoPt_stGBxMod
      P_CoPt_stGearRat: unqueued-sender-com-spec{data-element=CoPt_stGearRat, can-invalidate=false, init-value=CoPt_stGearRat_Cst}, provided-interface=IF_CoPt_stGearRat
      P_CoPt_tqMinGBxMsg: unqueued-sender-com-spec{data-element=CoPt_tqMinGBxMsg, can-invalidate=false, init-value=CoPt_tqMinGBxMsg_Cst}, provided-interface=IF_CoPt_tqMinGBxMsg
      P_CoPt_tqReqClu: unqueued-sender-com-spec{data-element=CoPt_tqReqClu, can-invalidate=false, init-value=CoPt_tqReqClu_Cst}, provided-interface=IF_CoPt_tqReqClu
      P_CoPt_bAcvIdlCrawl: unqueued-sender-com-spec{data-element=CoPt_bAcvIdlCrawl, can-invalidate=false, init-value=CoPt_bAcvIdlCrawl_Cst}, provided-interface=IF_CoPt_bAcvIdlCrawl
      P_CoPt_bAcvNRegReq: unqueued-sender-com-spec{data-element=CoPt_bAcvNRegReq, can-invalidate=false, init-value=ConstantValue131}, provided-interface=IF_CoPt_bAcvNRegReq
      P_CoPt_bAcvSptTakeOff: unqueued-sender-com-spec{data-element=CoPt_bAcvSptTakeOff, can-invalidate=false, init-value=CoPt_bAcvSptTakeOff_Cst}, provided-interface=IF_CoPt_bAcvSptTakeOff
      P_CoPt_bAcvWupMod: unqueued-sender-com-spec{data-element=CoPt_bAcvWupMod, can-invalidate=false, init-value=CoPt_bAcvWupMod_Cst}, provided-interface=IF_CoPt_bAcvWupMod
      P_CoPt_bBrioUHAuth: unqueued-sender-com-spec{data-element=CoPt_bBrioUHAuth, can-invalidate=false, init-value=ConstantValue133}, provided-interface=IF_CoPt_bBrioUHAuth
      P_CoPt_bDiagSIPORng: unqueued-sender-com-spec{data-element=CoPt_bDiagSIPORng, can-invalidate=false, init-value=CoPt_bDiagSIPORng_Cst}, provided-interface=IF_CoPt_bDiagSIPORng
      P_CoPt_bFrzAC: unqueued-sender-com-spec{data-element=CoPt_bFrzAC, can-invalidate=false, init-value=ConstantValue135}, provided-interface=IF_CoPt_bFrzAC
      P_CoPt_bFrzEGR: unqueued-sender-com-spec{data-element=CoPt_bFrzEGR, can-invalidate=false, init-value=CoPt_bFrzEGR_Cst}, provided-interface=IF_CoPt_bFrzEGR
      P_CoPt_bFrzTrbSt: unqueued-sender-com-spec{data-element=CoPt_bFrzTrbSt, can-invalidate=false, init-value=CoPt_bFrzTrbSt_Cst}, provided-interface=IF_CoPt_bFrzTrbSt
      P_CoPt_bInhEGR: unqueued-sender-com-spec{data-element=CoPt_bInhEGR, can-invalidate=false, init-value=ConstantValue137}, provided-interface=IF_CoPt_bInhEGR
      P_CoPt_bInhRecup: unqueued-sender-com-spec{data-element=CoPt_bInhRecup, can-invalidate=false, init-value=ConstantValue139}, provided-interface=IF_CoPt_bInhRecup
      P_CoPt_bInjCutDynAuth3: unqueued-sender-com-spec{data-element=CoPt_bInjCutDynAuth3, can-invalidate=false, init-value=ConstantValue141}, provided-interface=IF_CoPt_bInjCutDynAuth3
      P_CoPt_bPrepSIP: unqueued-sender-com-spec{data-element=CoPt_bPrepSIP, can-invalidate=false, init-value=ConstantValue143}, provided-interface=IF_CoPt_bPrepSIP
      P_CoPt_bPrfModReq: unqueued-sender-com-spec{data-element=CoPt_bPrfModReq, can-invalidate=false, init-value=ConstantValue145}, provided-interface=IF_CoPt_bPrfModReq
      P_CoPt_bSIP: unqueued-sender-com-spec{data-element=CoPt_bSIP, can-invalidate=false, init-value=ConstantValue147}, provided-interface=IF_CoPt_bSIP
      P_CoPt_bSmkFil: unqueued-sender-com-spec{data-element=CoPt_bSmkFil, can-invalidate=false, init-value=CoPt_bSmkFil_Cst}, provided-interface=IF_CoPt_bSmkFil
      P_CoPt_bTakeOff: unqueued-sender-com-spec{data-element=CoPt_bTakeOff, can-invalidate=false, init-value=ConstantValue149}, provided-interface=IF_CoPt_bTakeOff
      P_CoPt_bTqAltFrzReq: unqueued-sender-com-spec{data-element=CoPt_bTqAltFrzReq, can-invalidate=false, init-value=ConstantValue151}, provided-interface=IF_CoPt_bTqAltFrzReq
      P_CoPt_bTqAltGrdLimReq: unqueued-sender-com-spec{data-element=CoPt_bTqAltGrdLimReq, can-invalidate=false, init-value=ConstantValue153}, provided-interface=IF_CoPt_bTqAltGrdLimReq
      P_CoPt_bTqTx: unqueued-sender-com-spec{data-element=CoPt_bTqTx, can-invalidate=false, init-value=ConstantValue155}, provided-interface=IF_CoPt_bTqTx
      P_CoPt_facAntiJerk: unqueued-sender-com-spec{data-element=CoPt_facAntiJerk, can-invalidate=false, init-value=ConstantValue157}, provided-interface=IF_CoPt_facAntiJerk
      P_CoPt_idxPtSpt: unqueued-sender-com-spec{data-element=CoPt_idxPtSpt, can-invalidate=false, init-value=ConstantValue159}, provided-interface=IF_CoPt_idxPtSpt
      P_CoPt_noCylCutAuth: unqueued-sender-com-spec{data-element=CoPt_noCylCutAuth, can-invalidate=false, init-value=ConstantValue161}, provided-interface=IF_CoPt_noCylCutAuth
      P_CoPt_noDrivFilTyp: unqueued-sender-com-spec{data-element=CoPt_noDrivFilTyp, can-invalidate=false, init-value=ConstantValue163}, provided-interface=IF_CoPt_noDrivFilTyp
      P_CoPt_noEgdGear: unqueued-sender-com-spec{data-element=CoPt_noEgdGear, can-invalidate=false, init-value=ConstantValue165}, provided-interface=IF_CoPt_noEgdGear
      P_CoPt_noTarGear: unqueued-sender-com-spec{data-element=CoPt_noTarGear, can-invalidate=false, init-value=ConstantValue167}, provided-interface=IF_CoPt_noTarGear
      P_CoPt_nPrimShaft: unqueued-sender-com-spec{data-element=CoPt_nPrimShaft, can-invalidate=false, init-value=ConstantValue169}, provided-interface=IF_CoPt_nPrimShaft
      P_CoPt_nTar: unqueued-sender-com-spec{data-element=CoPt_nTar, can-invalidate=false, init-value=ConstantValue171}, provided-interface=IF_CoPt_nTar
      P_CoPt_nTrb: unqueued-sender-com-spec{data-element=CoPt_nTrb, can-invalidate=false, init-value=ConstantValue173}, provided-interface=IF_CoPt_nTrb
      P_CoPt_posnLev: unqueued-sender-com-spec{data-element=CoPt_posnLev, can-invalidate=false, init-value=ConstantValue175}, provided-interface=IF_CoPt_posnLev
      P_CoPt_rCnvTq: unqueued-sender-com-spec{data-element=CoPt_rCnvTq, can-invalidate=false, init-value=CoPt_rCnvTq_Cst}, provided-interface=IF_CoPt_rCnvTq
      P_CoPt_stClu: unqueued-sender-com-spec{data-element=CoPt_stClu, can-invalidate=false, init-value=ConstantValue177}, provided-interface=IF_CoPt_stClu
      P_CoPt_stCnvCluFil: unqueued-sender-com-spec{data-element=CoPt_stCnvCluFil, can-invalidate=false, init-value=ConstantValue179}, provided-interface=IF_CoPt_stCnvCluFil
      P_CoPt_stCpl: unqueued-sender-com-spec{data-element=CoPt_stCpl, can-invalidate=false, init-value=ConstantValue181}, provided-interface=IF_CoPt_stCpl
      P_CoPt_stDragRed: unqueued-sender-com-spec{data-element=CoPt_stDragRed, can-invalidate=false, init-value=ConstantValue183}, provided-interface=IF_CoPt_stDragRed
      P_CoPt_stDrvTra: unqueued-sender-com-spec{data-element=CoPt_stDrvTra, can-invalidate=false, init-value=ConstantValue185}, provided-interface=IF_CoPt_stDrvTra
      P_CoPt_stGSTyp: unqueued-sender-com-spec{data-element=CoPt_stGSTyp, can-invalidate=false, init-value=ConstantValue187}, provided-interface=IF_CoPt_stGSTyp
      P_CoPt_tiDeacPrfMod: unqueued-sender-com-spec{data-element=CoPt_tiDeacPrfMod, can-invalidate=false, init-value=ConstantValue189}, provided-interface=IF_CoPt_tiDeacPrfMod
      P_CoPt_tOilGBx: unqueued-sender-com-spec{data-element=CoPt_tOilGBx, can-invalidate=false, init-value=ConstantValue191}, provided-interface=IF_CoPt_tOilGBx
      P_CoPt_tqAirMaxGBx: unqueued-sender-com-spec{data-element=CoPt_tqAirMaxGBx, can-invalidate=false, init-value=ConstantValue193}, provided-interface=IF_CoPt_tqAirMaxGBx
      P_CoPt_tqCnvClu: unqueued-sender-com-spec{data-element=CoPt_tqCnvClu, can-invalidate=false, init-value=ConstantValue195}, provided-interface=IF_CoPt_tqCnvClu
      P_CoPt_tqMaxClu: unqueued-sender-com-spec{data-element=CoPt_tqMaxClu, can-invalidate=false, init-value=ConstantValue197}, provided-interface=IF_CoPt_tqMaxClu
      P_CoPt_tqMaxGBx: unqueued-sender-com-spec{data-element=CoPt_tqMaxGBx, can-invalidate=false, init-value=ConstantValue199}, provided-interface=IF_CoPt_tqMaxGBx
      P_CoPt_tqMaxGBx_nReg: unqueued-sender-com-spec{data-element=CoPt_tqMaxGBx_nReg, can-invalidate=false, init-value=ConstantValue201}, provided-interface=IF_CoPt_tqMaxGBx_nReg
      P_CoPt_tqMaxGBxAir: unqueued-sender-com-spec{data-element=CoPt_tqMaxGBxAir, can-invalidate=false, init-value=CoPt_tqMaxGBxAir_Cst}, provided-interface=IF_CoPt_tqMaxGBxAir
      P_CoPt_bDeacCllIt: unqueued-sender-com-spec{data-element=CoPt_bDeacCllIt, can-invalidate=false, init-value=ConstantValue203}, provided-interface=IF_CoPt_bDeacCllIt
      P_CoPt_tqCord_tqGBx: unqueued-sender-com-spec{data-element=CoPt_tqCord_tqGBx, can-invalidate=false, init-value=ConstantValue205}, provided-interface=IF_CoPt_tqCord_tqGBx
      P_CoPt_tqDrvFil: unqueued-sender-com-spec{data-element=CoPt_tqDrvFil, can-invalidate=false, init-value=CoPt_tqDrvFil_Cst}, provided-interface=IF_CoPt_tqDrvFil
      P_CoPt_tqDrvRaw: unqueued-sender-com-spec{data-element=CoPt_tqDrvRaw, can-invalidate=false, init-value=CoPt_tqDrvRaw_Cst}, provided-interface=IF_CoPt_tqDrvRaw
      P_CoPt_tqIdcAirDslCord_nReg: unqueued-sender-com-spec{data-element=CoPt_tqIdcAirDslCord_nReg, can-invalidate=false, init-value=ConstantValue207}, provided-interface=IF_CoPt_tqIdcAirDslCord_nReg
      P_CoPt_tqIdcCord_nRegReq: unqueued-sender-com-spec{data-element=CoPt_tqIdcCord_nRegReq, can-invalidate=false, init-value=CoPt_tqIdcCord_nRegReq_Cst}, provided-interface=IF_CoPt_tqIdcCord_nRegReq
      P_CoPt_bAcvCll: unqueued-sender-com-spec{data-element=CoPt_bAcvCll, can-invalidate=false, init-value=ConstantValue209}, provided-interface=IF_CoPt_bAcvCll
      P_CoPt_bAcvNCross: unqueued-sender-com-spec{data-element=CoPt_bAcvNCross, can-invalidate=false, init-value=CoPt_bAcvNCross_Cst}, provided-interface=IF_CoPt_bAcvNCross
      P_CoPt_bTqAltFrzReq_nCross: unqueued-sender-com-spec{data-element=CoPt_bTqAltFrzReq_nCross, can-invalidate=false, init-value=ConstantValue211}, provided-interface=IF_CoPt_bTqAltFrzReq_nCross
      P_CoPt_tiTranCll: unqueued-sender-com-spec{data-element=CoPt_tiTranCll, can-invalidate=false, init-value=ConstantValue213}, provided-interface=IF_CoPt_tiTranCll
      P_CoPt_tqIdcReqCord_nRegReq: unqueued-sender-com-spec{data-element=CoPt_tqIdcReqCord_nRegReq, can-invalidate=false, init-value=ConstantValue215}, provided-interface=IF_CoPt_tqIdcReqCord_nRegReq
      P_CoPt_tqIncCll: unqueued-sender-com-spec{data-element=CoPt_tqIncCll, can-invalidate=false, init-value=ConstantValue217}, provided-interface=IF_CoPt_tqIncCll
      P_CoPt_tqAirDrvFil: unqueued-sender-com-spec{data-element=CoPt_tqAirDrvFil, can-invalidate=false, init-value=CoPt_tqAirDrvFil_Cst}, provided-interface=IF_CoPt_tqAirDrvFil
      P_CoPt_tqAirCord_tqGBx: unqueued-sender-com-spec{data-element=CoPt_tqAirCord_tqGBx, can-invalidate=false, init-value=ConstantValue219}, provided-interface=IF_CoPt_tqAirCord_tqGBx
      P_CoPt_tqIdcAirGslCord_nReg: unqueued-sender-com-spec{data-element=CoPt_tqIdcAirGslCord_nReg, can-invalidate=false, init-value=CoPt_tqIdcAirGslCord_nReg_Cst}, provided-interface=IF_CoPt_tqIdcAirGslCord_nReg
      P_CoPt_tqIdcAirCord_nCross: unqueued-sender-com-spec{data-element=CoPt_tqIdcAirCord_nCross, can-invalidate=false, init-value=ConstantValue221}, provided-interface=IF_CoPt_tqIdcAirCord_nCross
      P_CoPt_stVoltAltBoostReq: unqueued-sender-com-spec{data-element=CoPt_stVoltAltBoostReq, can-invalidate=false, init-value=ConstantValue223}, provided-interface=IF_CoPt_stVoltAltBoostReq
      P_CoPt_nPrimShaftTar: unqueued-sender-com-spec{data-element=CoPt_nPrimShaftTar, can-invalidate=false, init-value=CoPt_nPrimShaftTar_Cst}, provided-interface=IF_CoPt_nPrimShaftTar
      P_CoPt_tqFfNReg: unqueued-sender-com-spec{data-element=CoPt_tqFfNReg, can-invalidate=false, init-value=CoPt_tqFfNReg_Cst}, provided-interface=IF_CoPt_tqFfNReg
      P_CoPt_bEngCrawlAuth: unqueued-sender-com-spec{data-element=CoPt_bEngCrawlAuth, can-invalidate=false, init-value=CoPt_bEngCrawlAuth_Cst}, provided-interface=IF_CoPt_bEngCrawlAuth
      P_CoPt_stVehDirEstim: unqueued-sender-com-spec{data-element=CoPt_stVehDirEstim, can-invalidate=false, init-value=CoPt_stVehDirEstim_Cst}, provided-interface=IF_CoPt_stVehDirEstim
      P_CoPt_bSpdVehLoDet: unqueued-sender-com-spec{data-element=CoPt_bSpdVehLoDet, can-invalidate=false, init-value=CoPt_bSpdVehLoDet_Cst}, provided-interface=IF_CoPt_bSpdVehLoDet
      P_CoPt_bAcvTqNCord: unqueued-sender-com-spec{data-element=CoPt_bAcvTqNCord, can-invalidate=false, init-value=CoPt_bAcvTqNCord_Cst}, provided-interface=IF_CoPt_bAcvTqNCord
      P_CoPt_tqDrvRawTarGear: unqueued-sender-com-spec{data-element=CoPt_tqDrvRawTarGear, can-invalidate=false, init-value=CoPt_tqDrvRawTarGear_Cst}, provided-interface=IF_CoPt_tqDrvRawTarGear
      P_CoPt_bInhAC: unqueued-sender-com-spec{data-element=CoPt_bInhAC, can-invalidate=false, init-value=CoPt_bInhAC_Cst}, provided-interface=IF_CoPt_bInhAC
      P_CoPt_bAcvCycMod: unqueued-sender-com-spec{data-element=CoPt_bAcvCycMod, can-invalidate=false, init-value=CoPt_bAcvCycMod_Cst}, provided-interface=IF_CoPt_bAcvCycMod
  207 x constant specification:
    CoCha_tqEfcAirReqExt_Cst
      value:
        integer literal CoCha_tqEfcAirReqExt_Cst: type=DT_CoCha_tqEfcAirReqExt, value=0
    CoCha_tqEfcReqExt_Cst
      value:
        integer literal CoCha_tqEfcReqExt_Cst: type=DT_CoCha_tqEfcReqExt, value=0
    ConstantValue
      value:
        integer literal ConstantValue: type=DT_Ext_nEng, value=0
    ConstantValue1
      value:
        integer literal ConstantValue1: type=DT_Ext_posnGBxLev, value=0
    ConstantValue101
      value:
        boolean literal ConstantValue101: type=DT_CoPt_bPrepSIP, value=false
    ConstantValue103
      value:
        integer literal ConstantValue103: type=DT_CoPt_nTrb, value=0
    ConstantValue105
      value:
        integer literal ConstantValue105: type=DT_CoPt_tqIdcMaxGBxBuf, value=32000
    ConstantValue107
      value:
        integer literal ConstantValue107: type=DT_CoPt_tqMaxGBx, value=0
    ConstantValue109
      value:
        integer literal ConstantValue109: type=DT_TqSys_idxTqAccu, value=1
    ConstantValue11
      value:
        integer literal ConstantValue11: type=DT_TqSys_nTarIdl, value=0
    ConstantValue111
      value:
        integer literal ConstantValue111: type=DT_TreatTDC_nCkGrd, value=0
    ConstantValue113
      value:
        integer literal ConstantValue113: type=DT_TqCha_tqAirTqDecReq, value=0
    ConstantValue115
      value:
        integer literal ConstantValue115: type=DT_TqCha_tqAirTqIncReq, value=0
    ConstantValue117
      value:
        integer literal ConstantValue117: type=DT_TqSys_tqCkEfcAirFil, value=0
    ConstantValue119
      value:
        integer literal ConstantValue119: type=DT_TqSys_tqEfcAirIdl, value=0
    ConstantValue121
      value:
        boolean literal ConstantValue121: type=DT_CoPt_bAcvNRegReq, value=false
    ConstantValue123
      value:
        integer literal ConstantValue123: type=DT_CoPt_tqIdcAirMaxGBx, value=32000
    ConstantValue125
      value:
        boolean literal ConstantValue125: type=DT_CoPtUH_bRStrtTypAT, value=false
    ConstantValue127
      value:
        integer literal ConstantValue127: type=DT_Ext_tOilGBx, value=0
    ConstantValue129
      value:
        integer literal ConstantValue129: type=DT_Ext_dstVehTotMes, value=0
    ConstantValue13
      value:
        integer literal ConstantValue13: type=DT_Tra_noEgdGear, value=0
    ConstantValue131
      value:
        boolean literal ConstantValue131: type=DT_CoPt_bAcvNRegReq, value=false
    ConstantValue133
      value:
        boolean literal ConstantValue133: type=DT_CoPt_bBrioUHAuth, value=false
    ConstantValue135
      value:
        boolean literal ConstantValue135: type=DT_CoPt_bFrzAC, value=false
    ConstantValue137
      value:
        boolean literal ConstantValue137: type=DT_CoPt_bInhEGR, value=false
    ConstantValue139
      value:
        boolean literal ConstantValue139: type=DT_CoPt_bInhRecup, value=false
    ConstantValue141
      value:
        boolean literal ConstantValue141: type=DT_CoPt_bInjCutDynAuth3, value=false
    ConstantValue143
      value:
        boolean literal ConstantValue143: type=DT_CoPt_bPrepSIP, value=false
    ConstantValue145
      value:
        boolean literal ConstantValue145: type=DT_CoPt_bPrfModReq, value=false
    ConstantValue147
      value:
        boolean literal ConstantValue147: type=DT_CoPt_bSIP, value=false
    ConstantValue149
      value:
        boolean literal ConstantValue149: type=DT_CoPt_bTakeOff, value=false
    ConstantValue15
      value:
        integer literal ConstantValue15: type=DT_Tra_noTarGear, value=0
    ConstantValue151
      value:
        boolean literal ConstantValue151: type=DT_CoPt_bTqAltFrzReq, value=false
    ConstantValue153
      value:
        boolean literal ConstantValue153: type=DT_CoPt_bTqAltGrdLimReq, value=false
    ConstantValue155
      value:
        boolean literal ConstantValue155: type=DT_CoPt_bTqTx, value=false
    ConstantValue157
      value:
        integer literal ConstantValue157: type=DT_CoPt_facAntiJerk, value=0
    ConstantValue159
      value:
        integer literal ConstantValue159: type=DT_CoPt_idxPtSpt, value=0
    ConstantValue161
      value:
        integer literal ConstantValue161: type=DT_CoPt_noCylCutAuth, value=0
    ConstantValue163
      value:
        integer literal ConstantValue163: type=DT_CoPt_noDrivFilTyp, value=0
    ConstantValue165
      value:
        integer literal ConstantValue165: type=DT_CoPt_noEgdGear, value=0
    ConstantValue167
      value:
        integer literal ConstantValue167: type=DT_CoPt_noTarGear, value=0
    ConstantValue169
      value:
        integer literal ConstantValue169: type=DT_CoPt_nPrimShaft, value=0
    ConstantValue17
      value:
        integer literal ConstantValue17: type=DT_Tra_stGBxMod, value=0
    ConstantValue171
      value:
        integer literal ConstantValue171: type=DT_CoPt_nTar, value=3000
    ConstantValue173
      value:
        integer literal ConstantValue173: type=DT_CoPt_nTrb, value=0
    ConstantValue175
      value:
        integer literal ConstantValue175: type=DT_CoPt_posnLev, value=0
    ConstantValue177
      value:
        integer literal ConstantValue177: type=DT_CoPt_stClu, value=0
    ConstantValue179
      value:
        integer literal ConstantValue179: type=DT_CoPt_stCnvCluFil, value=0
    ConstantValue181
      value:
        integer literal ConstantValue181: type=DT_CoPt_stCpl, value=0
    ConstantValue183
      value:
        integer literal ConstantValue183: type=DT_CoPt_stDragRed, value=0
    ConstantValue185
      value:
        boolean literal ConstantValue185: type=DT_CoPt_stDrvTra, value=false
    ConstantValue187
      value:
        integer literal ConstantValue187: type=DT_CoPt_stGSTyp, value=5
    ConstantValue189
      value:
        integer literal ConstantValue189: type=DT_CoPt_tiDeacPrfMod, value=0
    ConstantValue19
      value:
        integer literal ConstantValue19: type=DT_CoPt_noEgdGearCordIt, value=0
    ConstantValue191
      value:
        integer literal ConstantValue191: type=DT_CoPt_tOilGBx, value=160
    ConstantValue193
      value:
        integer literal ConstantValue193: type=DT_CoPt_tqAirMaxGBx, value=32000
    ConstantValue195
      value:
        integer literal ConstantValue195: type=DT_CoPt_tqCnvClu, value=0
    ConstantValue197
      value:
        integer literal ConstantValue197: type=DT_CoPt_tqMaxClu, value=0
    ConstantValue199
      value:
        integer literal ConstantValue199: type=DT_CoPt_tqMaxGBx, value=0
    ConstantValue201
      value:
        integer literal ConstantValue201: type=DT_CoPt_tqMaxGBx_nReg, value=0
    ConstantValue203
      value:
        boolean literal ConstantValue203: type=DT_CoPt_bDeacCllIt, value=false
    ConstantValue205
      value:
        integer literal ConstantValue205: type=DT_CoPt_tqCord_tqGBx, value=0
    ConstantValue207
      value:
        integer literal ConstantValue207: type=DT_CoPt_tqIdcAirDslCord_nReg, value=0
    ConstantValue209
      value:
        boolean literal ConstantValue209: type=DT_CoPt_bAcvCll, value=false
    ConstantValue21
      value:
        integer literal ConstantValue21: type=DT_CoCha_tqEfcAirReq, value=0
    ConstantValue211
      value:
        boolean literal ConstantValue211: type=DT_CoPt_bTqAltFrzReq_nCross, value=false
    ConstantValue213
      value:
        integer literal ConstantValue213: type=DT_CoPt_tiTranCll, value=0
    ConstantValue215
      value:
        integer literal ConstantValue215: type=DT_CoPt_tqIdcReqCord_nRegReq, value=0
    ConstantValue217
      value:
        integer literal ConstantValue217: type=DT_CoPt_tqIncCll, value=0
    ConstantValue219
      value:
        integer literal ConstantValue219: type=DT_CoPt_tqAirCord_tqGBx, value=0
    ConstantValue221
      value:
        integer literal ConstantValue221: type=DT_CoPt_tqIdcAirCord_nCross, value=0
    ConstantValue223
      value:
        integer literal ConstantValue223: type=DT_CoPt_stVoltAltBoostReq, value=0
    ConstantValue23
      value:
        integer literal ConstantValue23: type=DT_CoVSCtl_rAccPEngTrv, value=0
    ConstantValue25
      value:
        integer literal ConstantValue25: type=DT_Ext_pAirExtMes, value=500
    ConstantValue27
      value:
        integer literal ConstantValue27: type=DT_Veh_spdVeh, value=0
    ConstantValue29
      value:
        integer literal ConstantValue29: type=DT_EngLim_tqEfcMaxNReg, value=0
    ConstantValue3
      value:
        boolean literal ConstantValue3: type=DT_InjSys_bFuCutOff, value=false
    ConstantValue31
      value:
        integer literal ConstantValue31: type=DT_EngLim_tqEfcMinCurCutOffTrv, value=0
    ConstantValue33
      value:
        integer literal ConstantValue33: type=DT_EngLim_tqEfcMinCurTrv, value=0
    ConstantValue35
      value:
        integer literal ConstantValue35: type=DT_EngLim_tqEfcNRegTakeOffLim, value=32000
    ConstantValue37
      value:
        boolean literal ConstantValue37: type=DT_EOM_bTWCHeatPha, value=false
    ConstantValue39
      value:
        integer literal ConstantValue39: type=DT_EOM_tiEngRun, value=0
    ConstantValue41
      value:
        integer literal ConstantValue41: type=DT_Ext_stGBxCf, value=0
    ConstantValue43
      value:
        integer literal ConstantValue43: type=DT_Ext_stTraTypCf, value=0
    ConstantValue45
      value:
        integer literal ConstantValue45: type=DT_Ext_tAir, value=20
    ConstantValue47
      value:
        integer literal ConstantValue47: type=DT_Ext_tCoMes, value=20
    ConstantValue49
      value:
        integer literal ConstantValue49: type=DT_TqSys_stTypPwtCf, value=0
    ConstantValue5
      value:
        integer literal ConstantValue5: type=DT_TqCmp_tqSumLossCmp, value=0
    ConstantValue51
      value:
        integer literal ConstantValue51: type=DT_TqSys_tqEfcIdl, value=0
    ConstantValue53
      value:
        integer literal ConstantValue53: type=DT_Cha_tqDynASRReq, value=0
    ConstantValue55
      value:
        integer literal ConstantValue55: type=DT_Cha_tqMSRReq, value=0
    ConstantValue57
      value:
        integer literal ConstantValue57: type=DT_CoCha_tqEfcReq, value=0
    ConstantValue59
      value:
        boolean literal ConstantValue59: type=DT_CoPt_bSIP, value=false
    ConstantValue61
      value:
        integer literal ConstantValue61: type=DT_TqCmp_tqCnvLoss, value=0
    ConstantValue63
      value:
        integer literal ConstantValue63: type=DT_TqLimEM_tqLimEM, value=0
    ConstantValue65
      value:
        integer literal ConstantValue65: type=DT_TqLimEM_tqLimEMExt, value=0
    ConstantValue67
      value:
        integer literal ConstantValue67: type=DT_TqSys_tqCkEfcFil, value=0
    ConstantValue69
      value:
        integer literal ConstantValue69: type=DT_TqSys_tqCkEfcFilExt, value=0
    ConstantValue7
      value:
        boolean literal ConstantValue7: type=DT_TqSys_bAcvCllIt, value=false
    ConstantValue71
      value:
        boolean literal ConstantValue71: type=DT_CoPt_bAcvNRegReqBuf, value=false
    ConstantValue73
      value:
        integer literal ConstantValue73: type=DT_CoPt_noTarGearCordBuf, value=0
    ConstantValue75
      value:
        integer literal ConstantValue75: type=DT_CoPt_noTarGearCordIt, value=0
    ConstantValue77
      value:
        integer literal ConstantValue77: type=DT_CoPt_nTar, value=3000
    ConstantValue79
      value:
        integer literal ConstantValue79: type=DT_CoPt_nTarBuf, value=3000
    ConstantValue81
      value:
        integer literal ConstantValue81: type=DT_CoPt_tqIdcAirCordLim_tqGBx, value=0
    ConstantValue83
      value:
        integer literal ConstantValue83: type=DT_CoPt_tqMaxGBx_nRegBuf, value=32000
    ConstantValue85
      value:
        boolean literal ConstantValue85: type=DT_TqSys_bTqSysAcv, value=false
    ConstantValue87
      value:
        integer literal ConstantValue87: type=DT_Cha_stTqReq, value=0
    ConstantValue89
      value:
        boolean literal ConstantValue89: type=DT_CoPt_bSIPBuf, value=false
    ConstantValue9
      value:
        boolean literal ConstantValue9: type=DT_TqSys_bTypFu, value=false
    ConstantValue91
      value:
        integer literal ConstantValue91: type=DT_CoPt_tqIdcCordLimBuf_tqGBx, value=0
    ConstantValue93
      value:
        integer literal ConstantValue93: type=DT_Ext_tiTDC, value=100
    ConstantValue95
      value:
        integer literal ConstantValue95: type=DT_TqLimEM_tqIdcLimEM, value=0
    ConstantValue97
      value:
        boolean literal ConstantValue97: type=DT_TqSys_bInjCutDynReq, value=false
    ConstantValue99
      value:
        boolean literal ConstantValue99: type=DT_CoPt_bDeacCllBuf, value=false
    CoPt_bAcvCycMod_Cst
      value:
        boolean literal CoPt_bAcvCycMod_Cst: type=DT_CoPt_bAcvCycMod, value=true
    CoPt_bAcvDynTqResCrawl_Cst
      value:
        boolean literal CoPt_bAcvDynTqResCrawl_Cst: type=DT_CoPt_bAcvDynTqResCrawl, value=false
    CoPt_bAcvIdlCrawl_Cst
      value:
        boolean literal CoPt_bAcvIdlCrawl_Cst: type=DT_CoPt_bAcvIdlCrawl, value=false
    CoPt_bAcvNCross_Cst
      value:
        boolean literal CoPt_bAcvNCross_Cst: type=DT_CoPt_bAcvNCross, value=false
    CoPt_bAcvSptTakeOff_Cst
      value:
        boolean literal CoPt_bAcvSptTakeOff_Cst: type=DT_CoPt_bAcvSptTakeOff, value=false
    CoPt_bAcvStatTqResCrawl_Cst
      value:
        boolean literal CoPt_bAcvStatTqResCrawl_Cst: type=DT_CoPt_bAcvStatTqResCrawl, value=false
    CoPt_bAcvTqMaxEstim_Cst
      value:
        boolean literal CoPt_bAcvTqMaxEstim_Cst: type=DT_CoPt_bAcvTqMaxEstim, value=false
    CoPt_bAcvTqNCord_Cst
      value:
        boolean literal CoPt_bAcvTqNCord_Cst: type=DT_CoPt_bAcvTqNCord, value=false
    CoPt_bAcvTqNCordBuf_Cst
      value:
        boolean literal CoPt_bAcvTqNCordBuf_Cst: type=DT_CoPt_bAcvTqNCordBuf, value=false
    CoPt_bAcvWupMod_Cst
      value:
        boolean literal CoPt_bAcvWupMod_Cst: type=DT_CoPt_bAcvWupMod, value=false
    CoPt_bAuthCrawl_Cst
      value:
        boolean literal CoPt_bAuthCrawl_Cst: type=DT_CoPt_bAuthCrawl, value=true
    CoPt_bDeacCllNReg_irv_Cst
      value:
        boolean literal CoPt_bDeacCllNReg_irv_Cst: type=Boolean, value=false
    CoPt_bDiagSIPORng_Cst
      value:
        boolean literal CoPt_bDiagSIPORng_Cst: type=DT_CoPt_bDiagSIPORng, value=false
    CoPt_bEngCrawlAuth_Cst
      value:
        boolean literal CoPt_bEngCrawlAuth_Cst: type=DT_CoPt_bEngCrawlAuth, value=false
    CoPt_bFrzEGR_Cst
      value:
        boolean literal CoPt_bFrzEGR_Cst: type=DT_CoPt_bFrzEGR, value=false
    CoPt_bFrzTrbSt_Cst
      value:
        boolean literal CoPt_bFrzTrbSt_Cst: type=DT_CoPt_bFrzTrbSt, value=false
    CoPt_bInhAC_Cst
      value:
        boolean literal CoPt_bInhAC_Cst: type=DT_CoPt_bInhAC, value=false
    CoPt_bInhNCross_irv_Cst
      value:
        boolean literal CoPt_bInhNCross_irv_Cst: type=Boolean, value=false
    CoPt_bSmkFil_Cst
      value:
        boolean literal CoPt_bSmkFil_Cst: type=DT_CoPt_bSmkFil, value=false
    CoPt_bSpdVehLoDet_Cst
      value:
        boolean literal CoPt_bSpdVehLoDet_Cst: type=DT_CoPt_bSpdVehLoDet, value=true
    CoPt_bVldAcvNReg_irv_Cst
      value:
        boolean literal CoPt_bVldAcvNReg_irv_Cst: type=Boolean, value=false
    CoPt_facAntiJerkExt_Cst
      value:
        integer literal CoPt_facAntiJerkExt_Cst: type=DT_CoPt_facAntiJerkExt, value=256
    CoPt_idxPrfGBxMsg_Cst
      value:
        integer literal CoPt_idxPrfGBxMsg_Cst: type=DT_CoPt_idxPrfGBxMsg, value=128
    CoPt_nErrNReg_irv_Cst
      value:
        integer literal CoPt_nErrNReg_irv_Cst: type=SInt16, value=-32000
    CoPt_nMinTqMaxGBxMsg_Cst
      value:
        integer literal CoPt_nMinTqMaxGBxMsg_Cst: type=DT_CoPt_nMinTqMaxGBxMsg, value=0
    CoPt_noTypPIDGain_irv_Cst
      value:
        integer literal CoPt_noTypPIDGain_irv_Cst: type=UInt8, value=0
    CoPt_nPrimShaftTar_Cst
      value:
        integer literal CoPt_nPrimShaftTar_Cst: type=DT_CoPt_nPrimShaftTar, value=0
    CoPt_rCnvTq_Cst
      value:
        integer literal CoPt_rCnvTq_Cst: type=DT_CoPt_rCnvTq, value=1
    CoPt_stCrawl_Cst
      value:
        integer literal CoPt_stCrawl_Cst: type=DT_CoPt_stCrawl, value=0
    CoPt_stGBxMod_Cst
      value:
        integer literal CoPt_stGBxMod_Cst: type=DT_CoPt_stGBxMod, value=0
    CoPt_stGearRat_Cst
      value:
        integer literal CoPt_stGearRat_Cst: type=DT_CoPt_stGearRat, value=0
    CoPt_stPhaGS_irv_Cst
      value:
        integer literal CoPt_stPhaGS_irv_Cst: type=UInt8, value=0
    CoPt_stVehDirEstim_Cst
      value:
        integer literal CoPt_stVehDirEstim_Cst: type=DT_CoPt_stVehDirEstim, value=0
    CoPt_tqAirDrvFil_Cst
      value:
        integer literal CoPt_tqAirDrvFil_Cst: type=DT_CoPt_tqAirDrvFil, value=0
    CoPt_tqAirReqGBx_Cst
      value:
        integer literal CoPt_tqAirReqGBx_Cst: type=SInt16, value=-32000
    CoPt_tqDrvFil_Cst
      value:
        integer literal CoPt_tqDrvFil_Cst: type=DT_CoPt_tqDrvFil, value=0
    CoPt_tqDrvRaw_Cst
      value:
        integer literal CoPt_tqDrvRaw_Cst: type=DT_CoPt_tqDrvRaw, value=0
    CoPt_tqDrvRawTarGear_Cst
      value:
        integer literal CoPt_tqDrvRawTarGear_Cst: type=DT_CoPt_tqDrvRawTarGear, value=0
    CoPt_tqFfNReg_Cst
      value:
        integer literal CoPt_tqFfNReg_Cst: type=DT_CoPt_tqFfNReg, value=0
    CoPt_tqFfNRegBuf_Cst
      value:
        integer literal CoPt_tqFfNRegBuf_Cst: type=DT_CoPt_tqFfNRegBuf, value=0
    CoPt_tqGBxLossNReg_irv_Cst
      value:
        integer literal CoPt_tqGBxLossNReg_irv_Cst: type=SInt16, value=-32000
    CoPt_tqIdcAirGslCord_nReg_Cst
      value:
        integer literal CoPt_tqIdcAirGslCord_nReg_Cst: type=DT_CoPt_tqIdcAirGslCord_nReg, value=0
    CoPt_tqIdcCord_nRegReq_Cst
      value:
        integer literal CoPt_tqIdcCord_nRegReq_Cst: type=DT_CoPt_tqIdcCord_nRegReq, value=0
    CoPt_tqIdcNReg_irv_Cst
      value:
        integer literal CoPt_tqIdcNReg_irv_Cst: type=SInt16, value=-32000
    CoPt_tqIniNReg_irv_Cst
      value:
        integer literal CoPt_tqIniNReg_irv_Cst: type=SInt16, value=-32000
    CoPt_tqMaxGBxAir_Cst
      value:
        integer literal CoPt_tqMaxGBxAir_Cst: type=DT_CoPt_tqMaxGBxAir, value=32000
    CoPt_tqMinGBxMsg_Cst
      value:
        integer literal CoPt_tqMinGBxMsg_Cst: type=DT_CoPt_tqMinGBxMsg, value=0
    CoPt_tqReqClu_Cst
      value:
        integer literal CoPt_tqReqClu_Cst: type=DT_CoPt_tqReqClu, value=0
    CoPt_tqReqGBx_Cst
      value:
        integer literal CoPt_tqReqGBx_Cst: type=SInt16, value=-32000
    CoVSCtl_tqIdcSIPTar_Cst
      value:
        integer literal CoVSCtl_tqIdcSIPTar_Cst: type=DT_CoVSCtl_tqIdcSIPTar, value=0
    CoVSCtl_tqSIPTar_Cst
      value:
        integer literal CoVSCtl_tqSIPTar_Cst: type=DT_CoVSCtl_tqSIPTar, value=-32000
    EngLim_tqCkEfcATLimCordEL2_Cst
      value:
        integer literal EngLim_tqCkEfcATLimCordEL2_Cst: type=DT_EngLim_tqCkEfcATLimCordEL2, value=32000
    EngLim_tqCkEfcGBxLimCordEL2_Cst
      value:
        integer literal EngLim_tqCkEfcGBxLimCordEL2_Cst: type=DT_EngLim_tqCkEfcGBxLimCordEL2, value=32000
    TqCha_tqAirTqDecReqExt_Cst
      value:
        integer literal TqCha_tqAirTqDecReqExt_Cst: type=DT_TqCha_tqAirTqDecReqExt, value=32000
    TqCha_tqAirTqIncReqExt_Cst
      value:
        integer literal TqCha_tqAirTqIncReqExt_Cst: type=DT_TqCha_tqAirTqIncReqExt, value=-32000
    TqEst_tqIdcStrt_Cst
      value:
        integer literal TqEst_tqIdcStrt_Cst: type=DT_TqEst_tqIdcStrt, value=0
    TqSys_bAcvOvbReq_Cst
      value:
        boolean literal TqSys_bAcvOvbReq_Cst: type=DT_TqSys_bAcvOvbReq, value=false
    TqSys_EveSync_CoPtNCross_Cst
      value:
        boolean literal TqSys_EveSync_CoPtNCross_Cst: compu-method=SC_TqSys_EveSync_CoPtNCross, type=Boolean, value=false
    TqSys_EveSync_CoPtNReg_Cst
      value:
        boolean literal TqSys_EveSync_CoPtNReg_Cst: compu-method=SC_TqSys_EveSync_CoPtNReg, type=Boolean, value=false
    TqSys_EveSync_CoPtNRegCord_Cst
      value:
        boolean literal TqSys_EveSync_CoPtNRegCord_Cst: compu-method=SC_TqSys_EveSync_CoPtNRegCord, type=Boolean, value=false
    TqSys_stStrtEngTyp_Cst
      value:
        integer literal TqSys_stStrtEngTyp_Cst: type=DT_TqSys_stStrtEngTyp, value=0
    TqSys_tiDeacOvbReq_Cst
      value:
        integer literal TqSys_tiDeacOvbReq_Cst: type=DT_TqSys_tiDeacOvbReq, value=0
    TqSys_tqCkEfcAirFilExt_Cst
      value:
        integer literal TqSys_tqCkEfcAirFilExt_Cst: type=DT_TqSys_tqCkEfcAirFilExt, value=0
    Tra_bEngCrawlAuth_Cst
      value:
        boolean literal Tra_bEngCrawlAuth_Cst: type=DT_Tra_bEngCrawlAuth, value=false
    Tra_bFrzAC_Cst
      value:
        boolean literal Tra_bFrzAC_Cst: type=DT_Tra_bFrzAC, value=false
    Tra_bInhAC_Cst
      value:
        boolean literal Tra_bInhAC_Cst: type=DT_Tra_bInhAC, value=false
    Tra_bNRegReq_Cst
      value:
        boolean literal Tra_bNRegReq_Cst: type=DT_Tra_bNRegReq, value=false
    Tra_bNRegTyp_Cst
      value:
        boolean literal Tra_bNRegTyp_Cst: type=DT_Tra_bNRegTyp, value=true
    Tra_bSIP_Cst
      value:
        boolean literal Tra_bSIP_Cst: type=DT_Tra_bSIP, value=false
    Tra_bSIPPrep_Cst
      value:
        boolean literal Tra_bSIPPrep_Cst: type=DT_Tra_bSIPPrep, value=false
    Tra_bSpdVehLoDet_Cst
      value:
        boolean literal Tra_bSpdVehLoDet_Cst: type=DT_Tra_bSpdVehLoDet, value=false
    Tra_bTqTx_Cst
      value:
        boolean literal Tra_bTqTx_Cst: type=DT_Tra_bTqTx, value=false
    Tra_bVoltAltBoostReqGBx_Cst
      value:
        boolean literal Tra_bVoltAltBoostReqGBx_Cst: type=DT_Tra_bVoltAltBoostReqGBx, value=false
    Tra_idxPtSpt_Cst
      value:
        integer literal Tra_idxPtSpt_Cst: type=DT_Tra_idxPtSpt, value=0
    Tra_nPrimShaft_Cst
      value:
        integer literal Tra_nPrimShaft_Cst: type=DT_Tra_nPrimShaft, value=0
    Tra_nTar_Cst
      value:
        integer literal Tra_nTar_Cst: type=DT_Tra_nTar, value=3000
    Tra_nTrb_Cst
      value:
        integer literal Tra_nTrb_Cst: type=DT_Tra_nTrb, value=0
    Tra_rCnvTq_Cst
      value:
        integer literal Tra_rCnvTq_Cst: type=DT_Tra_rCnvTq, value=0
    Tra_stClu_Cst
      value:
        integer literal Tra_stClu_Cst: type=DT_Tra_stClu, value=0
    Tra_stCnvClu_Cst
      value:
        integer literal Tra_stCnvClu_Cst: type=DT_Tra_stCnvClu, value=0
    Tra_stCpl_Cst
      value:
        integer literal Tra_stCpl_Cst: type=DT_Tra_stCpl, value=0
    Tra_stCrawl_Cst
      value:
        integer literal Tra_stCrawl_Cst: type=DT_Tra_stCrawl, value=0
    Tra_stDragRed_Cst
      value:
        integer literal Tra_stDragRed_Cst: type=DT_Tra_stDragRed, value=0
    Tra_stGearRat_Cst
      value:
        integer literal Tra_stGearRat_Cst: type=DT_Tra_stGearRat, value=0
    Tra_stGSTyp_Cst
      value:
        integer literal Tra_stGSTyp_Cst: type=DT_Tra_stGSTyp, value=0
    Tra_stPhaGearShift_Cst
      value:
        integer literal Tra_stPhaGearShift_Cst: type=DT_Tra_stPhaGearShift, value=3
    Tra_stVehDirEstim_Cst
      value:
        integer literal Tra_stVehDirEstim_Cst: type=DT_Tra_stVehDirEstim, value=1
    Tra_tqCnvClu_Cst
      value:
        integer literal Tra_tqCnvClu_Cst: type=DT_Tra_tqCnvClu, value=0
    Tra_tqMaxClu_Cst
      value:
        integer literal Tra_tqMaxClu_Cst: type=DT_Tra_tqMaxClu, value=0
    Tra_tqMaxGBx_Cst
      value:
        integer literal Tra_tqMaxGBx_Cst: type=DT_Tra_tqMaxGBx, value=0
    Tra_tqReqClu_Cst
      value:
        integer literal Tra_tqReqClu_Cst: type=DT_Tra_tqReqClu, value=0
    Tra_tqReqGBx_Cst
      value:
        integer literal Tra_tqReqGBx_Cst: type=DT_Tra_tqReqGBx, value=0
  internal behavior IB_TraBVx: component=TRABVX
    timing event EV_TraBVx_032_TEV: mode-dependency=dependent-on-mode=[R_UCE_stWkuMainRelSt.RCD_stWkuMainRelSt.Invalid, R_UCE_stWkuMainRelSt.RCD_stWkuMainRelSt.PostMainWakeUp, R_UCE_stWkuMainRelSt.RCD_stWkuMainRelSt.PreMainWakeUp], start-on-event=RE_TraBVx_032_TEV, period=0.01
    mode switch event EV_TraBVx_001_MSE: start-on-event=RE_TraBVx_001_MSE, activation=ENTRY, mode=R_EcuM_CurrentMode.currentMode.RUN
    timing event EV_TraBVx_030_TEV: mode-dependency=dependent-on-mode=[R_UCE_stWkuMainRelSt.RCD_stWkuMainRelSt.Invalid, R_UCE_stWkuMainRelSt.RCD_stWkuMainRelSt.PostMainWakeUp, R_UCE_stWkuMainRelSt.RCD_stWkuMainRelSt.PreMainWakeUp], start-on-event=RE_TraBVx_030_TEV, period=0.01
    timing event EV_TraBVx_028_TEV: mode-dependency=dependent-on-mode=[R_UCE_stWkuMainRelSt.RCD_stWkuMainRelSt.Invalid, R_UCE_stWkuMainRelSt.RCD_stWkuMainRelSt.PostMainWakeUp, R_UCE_stWkuMainRelSt.RCD_stWkuMainRelSt.PreMainWakeUp], start-on-event=RE_TraBVx_028_TEV, period=0.01
    data received event EV_TraBVx_016_DRE: start-on-event=RE_TraBVx_016_DRE, data=R_TqSys_EveSync_CoPtNReg.TqSys_EveSync_CoPtNReg
    data received event EV_TraBVx_020_DRE: start-on-event=RE_TraBVx_020_DRE, data=R_TqSys_EveSync_CoPtNCross.TqSys_EveSync_CoPtNCross
    data received event EV_TraBVx_018_DRE: start-on-event=RE_TraBVx_018_DRE, data=R_TqSys_EveSync_CoPtNRegCord.TqSys_EveSync_CoPtNRegCord
    11 x inter runnable variable, all with sw-calibration-access=READ-WRITE, communication-approach=EXPLICIT:
      CoPt_tqAirReqGBx: type=SInt16, init-value=CoPt_tqAirReqGBx_Cst  # [01552_10_01264-TraBVx-I695(1)] - Consigne de couple BV en changement de rapport pour la branche air
      CoPt_stPhaGS_irv: type=UInt8, init-value=CoPt_stPhaGS_irv_Cst  # [01552_10_01264-TraBVx-I660(2)] - Phase de changement de rapport
      CoPt_tqIniNReg_irv: type=SInt16, init-value=CoPt_tqIniNReg_irv_Cst  # [01552_10_01264-TraBVx-I509(2)] - Couple d'initialisation du régulateur de régime
      CoPt_tqReqGBx: type=SInt16, init-value=CoPt_tqReqGBx_Cst  # [01552_10_01264-TraBVx-I694(1)] - Consigne de couple BV en changement de rapport
      CoPt_tqIdcNReg_irv: type=SInt16, init-value=CoPt_tqIdcNReg_irv_Cst  # [01552_10_01264-TraBVx-I667(1)] - Couple de régulation de régime boite
      CoPt_noTypPIDGain_irv: type=UInt8, init-value=CoPt_noTypPIDGain_irv_Cst  # [01552_10_01264-TraBVx-I662(1)] - Type de régulation de régime
      CoPt_nErrNReg_irv: type=SInt16, init-value=CoPt_nErrNReg_irv_Cst  # [01552_10_01264-TraBVx-I510(2)] - Ecart de régime de régulation
      CoPt_bVldAcvNReg_irv: type=Boolean, init-value=CoPt_bVldAcvNReg_irv_Cst  # [01552_10_01264-TraBVx-I511(2)] - Activation effective du régulateur de régime
      CoPt_tqGBxLossNReg_irv: type=SInt16, init-value=CoPt_tqGBxLossNReg_irv_Cst  # [01552_10_01264-TraBVx-I664(1)] - Couple de pertes BV en régulation de régime
      CoPt_bInhNCross_irv: type=Boolean, init-value=CoPt_bInhNCross_irv_Cst  # [01552_10_01264-TraBVx-I661(2)] - Demande d'inhibition de la stratégie de croisement de régime
      CoPt_bDeacCllNReg_irv: type=Boolean, init-value=CoPt_bDeacCllNReg_irv_Cst  # [01552_10_01264-TraBVx-I668(2)] - Autorisation de débouclage de la structure couple en fin de relance en régime
    7 x runnable:
      RE_TraBVx_018_DRE: read-variable=CoPt_tqIdcNReg_irv, written-variable=CoPt_bDeacCllNReg_irv  # 01552_10_01264-TraBVx-A018(2)
        12 x data receive point:
          dr_CoPt_bSIPBuf: data-element=R_CoPt_bSIPBuf.CoPt_bSIPBuf
          dr_CoPt_bAcvTqNCordBuf: data-element=R_CoPt_bAcvTqNCordBuf.CoPt_bAcvTqNCordBuf
          dr_Ext_nEng: data-element=R_Ext_nEng.Ext_nEng
          dr_TqSys_EveSync_CoPtNRegCord: data-element=R_TqSys_EveSync_CoPtNRegCord.TqSys_EveSync_CoPtNRegCord
          dr_TqSys_bInjCutDynReq: data-element=R_TqSys_bInjCutDynReq.TqSys_bInjCutDynReq
          dr_CoPt_tqIdcCordLimBuf_tqGBx: data-element=R_CoPt_tqIdcCordLimBuf_tqGBx.CoPt_tqIdcCordLimBuf_tqGBx
          dr_CoPt_bAcvNRegReqBuf: data-element=R_CoPt_bAcvNRegReqBuf.CoPt_bAcvNRegReqBuf
          dr_TqSys_bTypFu: data-element=R_TqSys_bTypFu.TqSys_bTypFu
          dr_Ext_tiTDC: data-element=R_Ext_tiTDC.Ext_tiTDC
          dr_TqLimEM_tqIdcLimEM: data-element=R_TqLimEM_tqIdcLimEM.TqLimEM_tqIdcLimEM
          dr_CoVSCtl_tqIdcSIPTar: data-element=R_CoVSCtl_tqIdcSIPTar.CoVSCtl_tqIdcSIPTar
          dr_Cha_stTqReq: data-element=R_Cha_stTqReq.Cha_stTqReq
        data send point ds_CoPt_tqIdcCord_nRegReq: data-element=P_CoPt_tqIdcCord_nRegReq.CoPt_tqIdcCord_nRegReq
        data send point ds_CoPt_tqIdcAirDslCord_nReg: data-element=P_CoPt_tqIdcAirDslCord_nReg.CoPt_tqIdcAirDslCord_nReg
      RE_TraBVx_001_MSE: written-variable=[CoPt_bVldAcvNReg_irv, CoPt_tqReqGBx, CoPt_tqAirReqGBx, CoPt_tqGBxLossNReg_irv, CoPt_tqIdcNReg_irv, CoPt_bInhNCross_irv, CoPt_stPhaGS_irv, CoPt_noTypPIDGain_irv, CoPt_bDeacCllNReg_irv, CoPt_tqIniNReg_irv, CoPt_nErrNReg_irv]  # 01552_10_01264-TraBVx-A001(4)
        81 x data send point:
          ds_CoPt_tqDrvFil: data-element=P_CoPt_tqDrvFil.CoPt_tqDrvFil
          ds_CoPt_bInhRecup: data-element=P_CoPt_bInhRecup.CoPt_bInhRecup
          ds_CoPt_posnLev: data-element=P_CoPt_posnLev.CoPt_posnLev
          ds_CoPt_bFrzAC: data-element=P_CoPt_bFrzAC.CoPt_bFrzAC
          ds_CoPt_noEgdGear: data-element=P_CoPt_noEgdGear.CoPt_noEgdGear
          ds_CoPt_bDeacCllIt: data-element=P_CoPt_bDeacCllIt.CoPt_bDeacCllIt
          ds_CoPt_stClu: data-element=P_CoPt_stClu.CoPt_stClu
          ds_CoPt_bAcvWupMod: data-element=P_CoPt_bAcvWupMod.CoPt_bAcvWupMod
          ds_CoPt_tqIdcCord_nRegReq: data-element=P_CoPt_tqIdcCord_nRegReq.CoPt_tqIdcCord_nRegReq
          ds_CoPt_bFrzTrbSt: data-element=P_CoPt_bFrzTrbSt.CoPt_bFrzTrbSt
          ds_CoPt_tqCord_tqGBx: data-element=P_CoPt_tqCord_tqGBx.CoPt_tqCord_tqGBx
          ds_CoPt_bSIP: data-element=P_CoPt_bSIP.CoPt_bSIP
          ds_CoPt_idxPrfGBxMsg: data-element=P_CoPt_idxPrfGBxMsg.CoPt_idxPrfGBxMsg
          ds_CoPt_rCnvTq: data-element=P_CoPt_rCnvTq.CoPt_rCnvTq
          ds_CoPt_bAcvCll: data-element=P_CoPt_bAcvCll.CoPt_bAcvCll
          ds_CoPt_bPrfModReq: data-element=P_CoPt_bPrfModReq.CoPt_bPrfModReq
          ds_CoPt_bInhAC: data-element=P_CoPt_bInhAC.CoPt_bInhAC
          ds_CoPt_bSmkFil: data-element=P_CoPt_bSmkFil.CoPt_bSmkFil
          ds_CoPt_stCnvCluFil: data-element=P_CoPt_stCnvCluFil.CoPt_stCnvCluFil
          ds_CoPt_tqCnvClu: data-element=P_CoPt_tqCnvClu.CoPt_tqCnvClu
          ds_CoPt_tqAirDrvFil: data-element=P_CoPt_tqAirDrvFil.CoPt_tqAirDrvFil
          ds_CoPt_nPrimShaftTar: data-element=P_CoPt_nPrimShaftTar.CoPt_nPrimShaftTar
          ds_CoPt_bSpdVehLoDet: data-element=P_CoPt_bSpdVehLoDet.CoPt_bSpdVehLoDet
          ds_CoPt_tqMaxGBxAir: data-element=P_CoPt_tqMaxGBxAir.CoPt_tqMaxGBxAir
          ds_CoPt_tqMaxClu: data-element=P_CoPt_tqMaxClu.CoPt_tqMaxClu
          ds_CoPt_bAcvDynTqResCrawl: data-element=P_CoPt_bAcvDynTqResCrawl.CoPt_bAcvDynTqResCrawl
          ds_CoPt_noDrivFilTyp: data-element=P_CoPt_noDrivFilTyp.CoPt_noDrivFilTyp
          ds_CoPt_stVoltAltBoostReq: data-element=P_CoPt_stVoltAltBoostReq.CoPt_stVoltAltBoostReq
          ds_CoPt_tqFfNReg: data-element=P_CoPt_tqFfNReg.CoPt_tqFfNReg
          ds_CoPt_nTrb: data-element=P_CoPt_nTrb.CoPt_nTrb
          ds_CoPt_tqMaxGBx_nReg: data-element=P_CoPt_tqMaxGBx_nReg.CoPt_tqMaxGBx_nReg
          ds_CoPt_bInjCutDynAuth3: data-element=P_CoPt_bInjCutDynAuth3.CoPt_bInjCutDynAuth3
          ds_CoPt_bAcvStatTqResCrawl: data-element=P_CoPt_bAcvStatTqResCrawl.CoPt_bAcvStatTqResCrawl
          ds_CoPt_nPrimShaft: data-element=P_CoPt_nPrimShaft.CoPt_nPrimShaft
          ds_CoPt_stGSTyp: data-element=P_CoPt_stGSTyp.CoPt_stGSTyp
          ds_CoPt_bAuthCrawl: data-element=P_CoPt_bAuthCrawl.CoPt_bAuthCrawl
          ds_CoPt_stCrawl: data-element=P_CoPt_stCrawl.CoPt_stCrawl
          ds_CoPt_tqAirCord_tqGBx: data-element=P_CoPt_tqAirCord_tqGBx.CoPt_tqAirCord_tqGBx
          ds_CoPt_bAcvTqNCord: data-element=P_CoPt_bAcvTqNCord.CoPt_bAcvTqNCord
          ds_CoPt_tOilGBx: data-element=P_CoPt_tOilGBx.CoPt_tOilGBx
          ds_CoPt_bAcvCycMod: data-element=P_CoPt_bAcvCycMod.CoPt_bAcvCycMod
          ds_CoPt_tqMinGBxMsg: data-element=P_CoPt_tqMinGBxMsg.CoPt_tqMinGBxMsg
          ds_CoPt_tqDrvRawTarGear: data-element=P_CoPt_tqDrvRawTarGear.CoPt_tqDrvRawTarGear
          ds_CoPt_tqAirMaxGBx: data-element=P_CoPt_tqAirMaxGBx.CoPt_tqAirMaxGBx
          ds_CoPt_bTakeOff: data-element=P_CoPt_bTakeOff.CoPt_bTakeOff
          ds_CoPt_stGBxMod: data-element=P_CoPt_stGBxMod.CoPt_stGBxMod
          ds_CoPt_nMinTqMaxGBxMsg: data-element=P_CoPt_nMinTqMaxGBxMsg.CoPt_nMinTqMaxGBxMsg
          ds_CoPt_bAcvNRegReq: data-element=P_CoPt_bAcvNRegReq.CoPt_bAcvNRegReq
          ds_CoPt_stCpl: data-element=P_CoPt_stCpl.CoPt_stCpl
          ds_CoPt_tqReqClu: data-element=P_CoPt_tqReqClu.CoPt_tqReqClu
          ds_CoPt_stDrvTra: data-element=P_CoPt_stDrvTra.CoPt_stDrvTra
          ds_CoPt_bTqAltFrzReq_nCross: data-element=P_CoPt_bTqAltFrzReq_nCross.CoPt_bTqAltFrzReq_nCross
          ds_CoPt_bInhEGR: data-element=P_CoPt_bInhEGR.CoPt_bInhEGR
          ds_CoPt_facAntiJerk: data-element=P_CoPt_facAntiJerk.CoPt_facAntiJerk
          ds_CoPt_idxPtSpt: data-element=P_CoPt_idxPtSpt.CoPt_idxPtSpt
          ds_CoPt_bTqAltFrzReq: data-element=P_CoPt_bTqAltFrzReq.CoPt_bTqAltFrzReq
          ds_CoPt_bAcvIdlCrawl: data-element=P_CoPt_bAcvIdlCrawl.CoPt_bAcvIdlCrawl
          ds_CoPt_stGearRat: data-element=P_CoPt_stGearRat.CoPt_stGearRat
          ds_CoPt_tqIdcReqCord_nRegReq: data-element=P_CoPt_tqIdcReqCord_nRegReq.CoPt_tqIdcReqCord_nRegReq
          ds_CoPt_bFrzEGR: data-element=P_CoPt_bFrzEGR.CoPt_bFrzEGR
          ds_CoPt_bPrepSIP: data-element=P_CoPt_bPrepSIP.CoPt_bPrepSIP
          ds_CoPt_bTqTx: data-element=P_CoPt_bTqTx.CoPt_bTqTx
          ds_CoPt_bAcvSptTakeOff: data-element=P_CoPt_bAcvSptTakeOff.CoPt_bAcvSptTakeOff
          ds_CoPt_tiTranCll: data-element=P_CoPt_tiTranCll.CoPt_tiTranCll
          ds_CoPt_tqIdcAirGslCord_nReg: data-element=P_CoPt_tqIdcAirGslCord_nReg.CoPt_tqIdcAirGslCord_nReg
          ds_CoPt_bEngCrawlAuth: data-element=P_CoPt_bEngCrawlAuth.CoPt_bEngCrawlAuth
          ds_CoPt_noCylCutAuth: data-element=P_CoPt_noCylCutAuth.CoPt_noCylCutAuth
          ds_CoPt_stVehDirEstim: data-element=P_CoPt_stVehDirEstim.CoPt_stVehDirEstim
          ds_CoPt_bAcvNCross: data-element=P_CoPt_bAcvNCross.CoPt_bAcvNCross
          ds_CoPt_bDiagSIPORng: data-element=P_CoPt_bDiagSIPORng.CoPt_bDiagSIPORng
          ds_CoPt_bTqAltGrdLimReq: data-element=P_CoPt_bTqAltGrdLimReq.CoPt_bTqAltGrdLimReq
          ds_CoPt_bBrioUHAuth: data-element=P_CoPt_bBrioUHAuth.CoPt_bBrioUHAuth
          ds_CoPt_tiDeacPrfMod: data-element=P_CoPt_tiDeacPrfMod.CoPt_tiDeacPrfMod
          ds_CoPt_tqMaxGBx: data-element=P_CoPt_tqMaxGBx.CoPt_tqMaxGBx
          ds_CoPt_tqIdcAirDslCord_nReg: data-element=P_CoPt_tqIdcAirDslCord_nReg.CoPt_tqIdcAirDslCord_nReg
          ds_CoPt_tqIdcAirCord_nCross: data-element=P_CoPt_tqIdcAirCord_nCross.CoPt_tqIdcAirCord_nCross
          ds_CoPt_tqDrvRaw: data-element=P_CoPt_tqDrvRaw.CoPt_tqDrvRaw
          ds_CoPt_tqIncCll: data-element=P_CoPt_tqIncCll.CoPt_tqIncCll
          ds_CoPt_stDragRed: data-element=P_CoPt_stDragRed.CoPt_stDragRed
          ds_CoPt_noTarGear: data-element=P_CoPt_noTarGear.CoPt_noTarGear
          ds_CoPt_nTar: data-element=P_CoPt_nTar.CoPt_nTar
      RE_TraBVx_016_DRE: read-variable=[CoPt_tqGBxLossNReg_irv, CoPt_nErrNReg_irv, CoPt_noTypPIDGain_irv, CoPt_tqIniNReg_irv], written-variable=[CoPt_tqIdcNReg_irv, CoPt_bVldAcvNReg_irv]  # 01552_10_01264-TraBVx-A016(2)
        11 x data receive point:
          dr_CoPt_noTarGearCordBuf: data-element=R_CoPt_noTarGearCordBuf.CoPt_noTarGearCordBuf
          dr_Ext_nEng: data-element=R_Ext_nEng.Ext_nEng
          dr_TqSys_tqEfcIdl: data-element=R_TqSys_tqEfcIdl.TqSys_tqEfcIdl
          dr_CoPt_bAcvNRegReqBuf: data-element=R_CoPt_bAcvNRegReqBuf.CoPt_bAcvNRegReqBuf
          dr_EngLim_tqEfcMaxNReg: data-element=R_EngLim_tqEfcMaxNReg.EngLim_tqEfcMaxNReg
          dr_CoPt_tqFfNRegBuf: data-element=R_CoPt_tqFfNRegBuf.CoPt_tqFfNRegBuf
          dr_TqSys_EveSync_CoPtNReg: data-element=R_TqSys_EveSync_CoPtNReg.TqSys_EveSync_CoPtNReg
          dr_CoPt_nTarBuf: data-element=R_CoPt_nTarBuf.CoPt_nTarBuf
          dr_TqSys_bTqSysAcv: data-element=R_TqSys_bTqSysAcv.TqSys_bTqSysAcv
          dr_CoPt_tqMaxGBx_nRegBuf: data-element=R_CoPt_tqMaxGBx_nRegBuf.CoPt_tqMaxGBx_nRegBuf
          dr_TqCmp_tqSumLossCmp: data-element=R_TqCmp_tqSumLossCmp.TqCmp_tqSumLossCmp
      RE_TraBVx_028_TEV: written-variable=[CoPt_bInhNCross_irv, CoPt_noTypPIDGain_irv, CoPt_tqReqGBx, CoPt_tqAirReqGBx, CoPt_stPhaGS_irv, CoPt_tqGBxLossNReg_irv]  # 01552_10_01264-TraBVx-A028(3)
        64 x data receive point:
          dr_Ext_stTraTypCf: data-element=R_Ext_stTraTypCf.Ext_stTraTypCf
          dr_Tra_bFrzAC: data-element=R_Tra_bFrzAC.Tra_bFrzAC
          dr_Tra_stCrawl: data-element=R_Tra_stCrawl.Tra_stCrawl
          dr_Tra_bSIPPrep: data-element=R_Tra_bSIPPrep.Tra_bSIPPrep
          dr_Ext_tOilGBx: data-element=R_Ext_tOilGBx.Ext_tOilGBx
          dr_TqSys_bAcvCllIt: data-element=R_TqSys_bAcvCllIt.TqSys_bAcvCllIt
          dr_Tra_noTarGear: data-element=R_Tra_noTarGear.Tra_noTarGear
          dr_EOM_tiEngRun: data-element=R_EOM_tiEngRun.EOM_tiEngRun
          dr_Tra_stClu: data-element=R_Tra_stClu.Tra_stClu
          dr_Tra_stVehDirEstim: data-element=R_Tra_stVehDirEstim.Tra_stVehDirEstim
          dr_Ext_posnGBxLev: data-element=R_Ext_posnGBxLev.Ext_posnGBxLev
          dr_Tra_stGSTyp: data-element=R_Tra_stGSTyp.Tra_stGSTyp
          dr_TqSys_tiDeacOvbReq: data-element=R_TqSys_tiDeacOvbReq.TqSys_tiDeacOvbReq
          dr_Tra_nTar: data-element=R_Tra_nTar.Tra_nTar
          dr_CoPtUH_bRStrtTypAT: data-element=R_CoPtUH_bRStrtTypAT.CoPtUH_bRStrtTypAT
          dr_TqSys_stStrtEngTyp: data-element=R_TqSys_stStrtEngTyp.TqSys_stStrtEngTyp
          dr_TqSys_stTypPwtCf: data-element=R_TqSys_stTypPwtCf.TqSys_stTypPwtCf
          dr_TqSys_bTypFu: data-element=R_TqSys_bTypFu.TqSys_bTypFu
          dr_Tra_bSIP: data-element=R_Tra_bSIP.Tra_bSIP
          dr_TqSys_bAcvOvbReq: data-element=R_TqSys_bAcvOvbReq.TqSys_bAcvOvbReq
          dr_Ext_tCoMes: data-element=R_Ext_tCoMes.Ext_tCoMes
          dr_CoPt_noEgdGearCordIt: data-element=R_CoPt_noEgdGearCordIt.CoPt_noEgdGearCordIt
          dr_EngLim_tqEfcMinCurTrv: data-element=R_EngLim_tqEfcMinCurTrv.EngLim_tqEfcMinCurTrv
          dr_Tra_bVoltAltBoostReqGBx: data-element=R_Tra_bVoltAltBoostReqGBx.Tra_bVoltAltBoostReqGBx
          dr_Ext_nEng: data-element=R_Ext_nEng.Ext_nEng
          dr_Tra_stGearRat: data-element=R_Tra_stGearRat.Tra_stGearRat
          dr_Tra_bSpdVehLoDet: data-element=R_Tra_bSpdVehLoDet.Tra_bSpdVehLoDet
          dr_Tra_bInhAC: data-element=R_Tra_bInhAC.Tra_bInhAC
          dr_Ext_pAirExtMes: data-element=R_Ext_pAirExtMes.Ext_pAirExtMes
          dr_CoVSCtl_tqSIPTar: data-element=R_CoVSCtl_tqSIPTar.CoVSCtl_tqSIPTar
          dr_Tra_bTqTx: data-element=R_Tra_bTqTx.Tra_bTqTx
          dr_Tra_noEgdGear: data-element=R_Tra_noEgdGear.Tra_noEgdGear
          dr_Tra_bEngCrawlAuth: data-element=R_Tra_bEngCrawlAuth.Tra_bEngCrawlAuth
          dr_Tra_idxPtSpt: data-element=R_Tra_idxPtSpt.Tra_idxPtSpt
          dr_EOM_bTWCHeatPha: data-element=R_EOM_bTWCHeatPha.EOM_bTWCHeatPha
          dr_Tra_stGBxMod: data-element=R_Tra_stGBxMod.Tra_stGBxMod
          dr_Tra_nTrb: data-element=R_Tra_nTrb.Tra_nTrb
          dr_EngLim_tqEfcMinCurCutOffTrv: data-element=R_EngLim_tqEfcMinCurCutOffTrv.EngLim_tqEfcMinCurCutOffTrv
          dr_Tra_tqReqGBx: data-element=R_Tra_tqReqGBx.Tra_tqReqGBx
          dr_Tra_bNRegTyp: data-element=R_Tra_bNRegTyp.Tra_bNRegTyp
          dr_Ext_dstVehTotMes: data-element=R_Ext_dstVehTotMes.Ext_dstVehTotMes
          dr_Ext_stGBxCf: data-element=R_Ext_stGBxCf.Ext_stGBxCf
          dr_InjSys_bFuCutOff: data-element=R_InjSys_bFuCutOff.InjSys_bFuCutOff
          dr_Tra_stCnvClu: data-element=R_Tra_stCnvClu.Tra_stCnvClu
          dr_Tra_bNRegReq: data-element=R_Tra_bNRegReq.Tra_bNRegReq
          dr_Tra_tqCnvClu: data-element=R_Tra_tqCnvClu.Tra_tqCnvClu
          dr_TqSys_nTarIdl: data-element=R_TqSys_nTarIdl.TqSys_nTarIdl
          dr_CoCha_tqEfcAirReq: data-element=R_CoCha_tqEfcAirReq.CoCha_tqEfcAirReq
          dr_TqSys_tqEfcIdl: data-element=R_TqSys_tqEfcIdl.TqSys_tqEfcIdl
          dr_Tra_nPrimShaft: data-element=R_Tra_nPrimShaft.Tra_nPrimShaft
          dr_CoVSCtl_rAccPEngTrv: data-element=R_CoVSCtl_rAccPEngTrv.CoVSCtl_rAccPEngTrv
          dr_Tra_tqMaxClu: data-element=R_Tra_tqMaxClu.Tra_tqMaxClu
          dr_Tra_tqReqClu: data-element=R_Tra_tqReqClu.Tra_tqReqClu
          dr_Ext_tAir: data-element=R_Ext_tAir.Ext_tAir
          dr_TqCmp_tqSumLossCmp: data-element=R_TqCmp_tqSumLossCmp.TqCmp_tqSumLossCmp
          dr_Tra_stDragRed: data-element=R_Tra_stDragRed.Tra_stDragRed
          dr_CoPt_facAntiJerkExt: data-element=R_CoPt_facAntiJerkExt.CoPt_facAntiJerkExt
          dr_EngLim_tqEfcMaxNReg: data-element=R_EngLim_tqEfcMaxNReg.EngLim_tqEfcMaxNReg
          dr_Veh_spdVeh: data-element=R_Veh_spdVeh.Veh_spdVeh
          dr_Tra_tqMaxGBx: data-element=R_Tra_tqMaxGBx.Tra_tqMaxGBx
          dr_Tra_stCpl: data-element=R_Tra_stCpl.Tra_stCpl
          dr_Tra_rCnvTq: data-element=R_Tra_rCnvTq.Tra_rCnvTq
          dr_EngLim_tqEfcNRegTakeOffLim: data-element=R_EngLim_tqEfcNRegTakeOffLim.EngLim_tqEfcNRegTakeOffLim
          dr_Tra_stPhaGearShift: data-element=R_Tra_stPhaGearShift.Tra_stPhaGearShift
        64 x data send point:
          ds_CoPt_posnLev: data-element=P_CoPt_posnLev.CoPt_posnLev
          ds_CoPt_bInhRecup: data-element=P_CoPt_bInhRecup.CoPt_bInhRecup
          ds_CoPt_bInhEGR: data-element=P_CoPt_bInhEGR.CoPt_bInhEGR
          ds_CoPt_tiDeacPrfMod: data-element=P_CoPt_tiDeacPrfMod.CoPt_tiDeacPrfMod
          ds_CoPt_tqMaxGBx_nReg: data-element=P_CoPt_tqMaxGBx_nReg.CoPt_tqMaxGBx_nReg
          ds_CoPt_bAcvNRegReq: data-element=P_CoPt_bAcvNRegReq.CoPt_bAcvNRegReq
          ds_CoPt_bSpdVehLoDet: data-element=P_CoPt_bSpdVehLoDet.CoPt_bSpdVehLoDet
          ds_CoPt_bTqAltFrzReq: data-element=P_CoPt_bTqAltFrzReq.CoPt_bTqAltFrzReq
          ds_CoPt_stCnvCluFil: data-element=P_CoPt_stCnvCluFil.CoPt_stCnvCluFil
          ds_CoPt_rCnvTq: data-element=P_CoPt_rCnvTq.CoPt_rCnvTq
          ds_CoPt_nPrimShaft: data-element=P_CoPt_nPrimShaft.CoPt_nPrimShaft
          ds_CoPt_bFrzAC: data-element=P_CoPt_bFrzAC.CoPt_bFrzAC
          ds_CoPt_nPrimShaftTar: data-element=P_CoPt_nPrimShaftTar.CoPt_nPrimShaftTar
          ds_CoPt_bBrioUHAuth: data-element=P_CoPt_bBrioUHAuth.CoPt_bBrioUHAuth
          ds_CoPt_idxPtSpt: data-element=P_CoPt_idxPtSpt.CoPt_idxPtSpt
          ds_CoPt_bAcvDynTqResCrawl: data-element=P_CoPt_bAcvDynTqResCrawl.CoPt_bAcvDynTqResCrawl
          ds_CoPt_stDragRed: data-element=P_CoPt_stDragRed.CoPt_stDragRed
          ds_CoPt_bTakeOff: data-element=P_CoPt_bTakeOff.CoPt_bTakeOff
          ds_CoPt_tqMaxClu: data-element=P_CoPt_tqMaxClu.CoPt_tqMaxClu
          ds_CoPt_bAuthCrawl: data-element=P_CoPt_bAuthCrawl.CoPt_bAuthCrawl
          ds_CoPt_facAntiJerk: data-element=P_CoPt_facAntiJerk.CoPt_facAntiJerk
          ds_CoPt_tqMinGBxMsg: data-element=P_CoPt_tqMinGBxMsg.CoPt_tqMinGBxMsg
          ds_CoPt_stClu: data-element=P_CoPt_stClu.CoPt_stClu
          ds_CoPt_bAcvStatTqResCrawl: data-element=P_CoPt_bAcvStatTqResCrawl.CoPt_bAcvStatTqResCrawl
          ds_CoPt_tqAirMaxGBx: data-element=P_CoPt_tqAirMaxGBx.CoPt_tqAirMaxGBx
          ds_CoPt_noCylCutAuth: data-element=P_CoPt_noCylCutAuth.CoPt_noCylCutAuth
          ds_CoPt_tqReqClu: data-element=P_CoPt_tqReqClu.CoPt_tqReqClu
          ds_CoPt_bPrfModReq: data-element=P_CoPt_bPrfModReq.CoPt_bPrfModReq
          ds_CoPt_stGSTyp: data-element=P_CoPt_stGSTyp.CoPt_stGSTyp
          ds_CoPt_stCrawl: data-element=P_CoPt_stCrawl.CoPt_stCrawl
          ds_CoPt_tqMaxGBx: data-element=P_CoPt_tqMaxGBx.CoPt_tqMaxGBx
          ds_CoPt_bTqTx: data-element=P_CoPt_bTqTx.CoPt_bTqTx
          ds_CoPt_bInjCutDynAuth3: data-element=P_CoPt_bInjCutDynAuth3.CoPt_bInjCutDynAuth3
          ds_CoPt_nTar: data-element=P_CoPt_nTar.CoPt_nTar
          ds_CoPt_bAcvTqNCord: data-element=P_CoPt_bAcvTqNCord.CoPt_bAcvTqNCord
          ds_CoPt_tOilGBx: data-element=P_CoPt_tOilGBx.CoPt_tOilGBx
          ds_CoPt_noDrivFilTyp: data-element=P_CoPt_noDrivFilTyp.CoPt_noDrivFilTyp
          ds_CoPt_bFrzEGR: data-element=P_CoPt_bFrzEGR.CoPt_bFrzEGR
          ds_CoPt_tqFfNReg: data-element=P_CoPt_tqFfNReg.CoPt_tqFfNReg
          ds_CoPt_tqMaxGBxAir: data-element=P_CoPt_tqMaxGBxAir.CoPt_tqMaxGBxAir
          ds_CoPt_bSmkFil: data-element=P_CoPt_bSmkFil.CoPt_bSmkFil
          ds_CoPt_bInhAC: data-element=P_CoPt_bInhAC.CoPt_bInhAC
          ds_CoPt_bDiagSIPORng: data-element=P_CoPt_bDiagSIPORng.CoPt_bDiagSIPORng
          ds_CoPt_bTqAltGrdLimReq: data-element=P_CoPt_bTqAltGrdLimReq.CoPt_bTqAltGrdLimReq
          ds_CoPt_stVoltAltBoostReq: data-element=P_CoPt_stVoltAltBoostReq.CoPt_stVoltAltBoostReq
          ds_CoPt_stCpl: data-element=P_CoPt_stCpl.CoPt_stCpl
          ds_CoPt_bSIP: data-element=P_CoPt_bSIP.CoPt_bSIP
          ds_CoPt_nMinTqMaxGBxMsg: data-element=P_CoPt_nMinTqMaxGBxMsg.CoPt_nMinTqMaxGBxMsg
          ds_CoPt_stGearRat: data-element=P_CoPt_stGearRat.CoPt_stGearRat
          ds_CoPt_bAcvSptTakeOff: data-element=P_CoPt_bAcvSptTakeOff.CoPt_bAcvSptTakeOff
          ds_CoPt_noEgdGear: data-element=P_CoPt_noEgdGear.CoPt_noEgdGear
          ds_CoPt_bPrepSIP: data-element=P_CoPt_bPrepSIP.CoPt_bPrepSIP
          ds_CoPt_stVehDirEstim: data-element=P_CoPt_stVehDirEstim.CoPt_stVehDirEstim
          ds_CoPt_idxPrfGBxMsg: data-element=P_CoPt_idxPrfGBxMsg.CoPt_idxPrfGBxMsg
          ds_CoPt_stDrvTra: data-element=P_CoPt_stDrvTra.CoPt_stDrvTra
          ds_CoPt_stGBxMod: data-element=P_CoPt_stGBxMod.CoPt_stGBxMod
          ds_CoPt_nTrb: data-element=P_CoPt_nTrb.CoPt_nTrb
          ds_CoPt_bFrzTrbSt: data-element=P_CoPt_bFrzTrbSt.CoPt_bFrzTrbSt
          ds_CoPt_bAcvIdlCrawl: data-element=P_CoPt_bAcvIdlCrawl.CoPt_bAcvIdlCrawl
          ds_CoPt_bAcvCycMod: data-element=P_CoPt_bAcvCycMod.CoPt_bAcvCycMod
          ds_CoPt_bAcvWupMod: data-element=P_CoPt_bAcvWupMod.CoPt_bAcvWupMod
          ds_CoPt_noTarGear: data-element=P_CoPt_noTarGear.CoPt_noTarGear
          ds_CoPt_bEngCrawlAuth: data-element=P_CoPt_bEngCrawlAuth.CoPt_bEngCrawlAuth
          ds_CoPt_tqCnvClu: data-element=P_CoPt_tqCnvClu.CoPt_tqCnvClu
        sync call SC_FRM_bInhCoPtSIP: operation=R_FRM_bInhCoPtSIP.GetFunctionPermission
        sync call SC_FRM_bInhCoPtCrawl: operation=R_FRM_bInhCoPtCrawl.GetFunctionPermission
      RE_TraBVx_032_TEV: read-variable=[CoPt_bInhNCross_irv, CoPt_bVldAcvNReg_irv, CoPt_noTypPIDGain_irv, CoPt_tqIdcNReg_irv], written-variable=[CoPt_tqIniNReg_irv, CoPt_nErrNReg_irv]  # 01552_10_01264-TraBVx-A032(0)
        16 x data receive point:
          dr_CoPt_nTar: data-element=R_CoPt_nTar.CoPt_nTar
          dr_TqSys_bTqSysAcv: data-element=R_TqSys_bTqSysAcv.TqSys_bTqSysAcv
          dr_CoPt_bAcvNRegReq: data-element=R_CoPt_bAcvNRegReq.CoPt_bAcvNRegReq
          dr_TqSys_bTypFu: data-element=R_TqSys_bTypFu.TqSys_bTypFu
          dr_Ext_nEng: data-element=R_Ext_nEng.Ext_nEng
          dr_CoPt_noEgdGearCordIt: data-element=R_CoPt_noEgdGearCordIt.CoPt_noEgdGearCordIt
          dr_CoPt_bAcvNCross: data-element=R_CoPt_bAcvNCross.CoPt_bAcvNCross
          dr_TqEst_tqIdcStrt: data-element=R_TqEst_tqIdcStrt.TqEst_tqIdcStrt
          dr_TqSys_idxTqAccu: data-element=R_TqSys_idxTqAccu.TqSys_idxTqAccu
          dr_CoPt_tqIdcAirMaxGBx: data-element=R_CoPt_tqIdcAirMaxGBx.CoPt_tqIdcAirMaxGBx
          dr_CoVSCtl_rAccPEngTrv: data-element=R_CoVSCtl_rAccPEngTrv.CoVSCtl_rAccPEngTrv
          dr_CoPt_tqIdcAirCordLim_tqGBx: data-element=R_CoPt_tqIdcAirCordLim_tqGBx.CoPt_tqIdcAirCordLim_tqGBx
          dr_TqCmp_tqSumLossCmp: data-element=R_TqCmp_tqSumLossCmp.TqCmp_tqSumLossCmp
          dr_Ext_stTraTypCf: data-element=R_Ext_stTraTypCf.Ext_stTraTypCf
          dr_CoPt_noTarGearCordIt: data-element=R_CoPt_noTarGearCordIt.CoPt_noTarGearCordIt
          dr_CoPt_nTrb: data-element=R_CoPt_nTrb.CoPt_nTrb
        data send point ds_CoPt_tqIdcAirGslCord_nReg: data-element=P_CoPt_tqIdcAirGslCord_nReg.CoPt_tqIdcAirGslCord_nReg
        data send point ds_CoPt_tqIdcAirCord_nCross: data-element=P_CoPt_tqIdcAirCord_nCross.CoPt_tqIdcAirCord_nCross
      RE_TraBVx_020_DRE: read-variable=[CoPt_bDeacCllNReg_irv, CoPt_bInhNCross_irv]  # 01552_10_01264-TraBVx-A020(2)
        20 x data receive point:
          dr_TqSys_EveSync_CoPtNCross: data-element=R_TqSys_EveSync_CoPtNCross.TqSys_EveSync_CoPtNCross
          dr_CoPt_tqDrvRaw: data-element=R_CoPt_tqDrvRaw.CoPt_tqDrvRaw
          dr_Cha_stTqReq: data-element=R_Cha_stTqReq.Cha_stTqReq
          dr_CoPt_tqIdcMaxGBxBuf: data-element=R_CoPt_tqIdcMaxGBxBuf.CoPt_tqIdcMaxGBxBuf
          dr_Ext_nEng: data-element=R_Ext_nEng.Ext_nEng
          dr_CoPt_tqIdcCord_nRegReq: data-element=R_CoPt_tqIdcCord_nRegReq.CoPt_tqIdcCord_nRegReq
          dr_CoPt_tqMaxGBx: data-element=R_CoPt_tqMaxGBx.CoPt_tqMaxGBx
          dr_CoPt_bSIPBuf: data-element=R_CoPt_bSIPBuf.CoPt_bSIPBuf
          dr_CoPt_bDeacCllBuf: data-element=R_CoPt_bDeacCllBuf.CoPt_bDeacCllBuf
          dr_CoPt_bAcvNRegReqBuf: data-element=R_CoPt_bAcvNRegReqBuf.CoPt_bAcvNRegReqBuf
          dr_CoVSCtl_rAccPEngTrv: data-element=R_CoVSCtl_rAccPEngTrv.CoVSCtl_rAccPEngTrv
          dr_CoPt_tqDrvFil: data-element=R_CoPt_tqDrvFil.CoPt_tqDrvFil
          dr_TreatTDC_nCkGrd: data-element=R_TreatTDC_nCkGrd.TreatTDC_nCkGrd
          dr_Ext_tiTDC: data-element=R_Ext_tiTDC.Ext_tiTDC
          dr_CoPt_bAcvTqNCordBuf: data-element=R_CoPt_bAcvTqNCordBuf.CoPt_bAcvTqNCordBuf
          dr_TqCmp_tqSumLossCmp: data-element=R_TqCmp_tqSumLossCmp.TqCmp_tqSumLossCmp
          dr_CoPt_nTrb: data-element=R_CoPt_nTrb.CoPt_nTrb
          dr_CoPt_bPrepSIP: data-element=R_CoPt_bPrepSIP.CoPt_bPrepSIP
          dr_CoPt_noEgdGearCordIt: data-element=R_CoPt_noEgdGearCordIt.CoPt_noEgdGearCordIt
          dr_TqSys_idxTqAccu: data-element=R_TqSys_idxTqAccu.TqSys_idxTqAccu
        6 x data send point:
          ds_CoPt_bTqAltFrzReq_nCross: data-element=P_CoPt_bTqAltFrzReq_nCross.CoPt_bTqAltFrzReq_nCross
          ds_CoPt_bAcvNCross: data-element=P_CoPt_bAcvNCross.CoPt_bAcvNCross
          ds_CoPt_tqIdcReqCord_nRegReq: data-element=P_CoPt_tqIdcReqCord_nRegReq.CoPt_tqIdcReqCord_nRegReq
          ds_CoPt_tiTranCll: data-element=P_CoPt_tiTranCll.CoPt_tiTranCll
          ds_CoPt_tqIncCll: data-element=P_CoPt_tqIncCll.CoPt_tqIncCll
          ds_CoPt_bAcvCll: data-element=P_CoPt_bAcvCll.CoPt_bAcvCll
      RE_TraBVx_030_TEV: read-variable=[CoPt_tqReqGBx, CoPt_tqAirReqGBx]  # 01552_10_01264-TraBVx-A030(4)
        28 x data receive point:
          dr_CoCha_tqEfcAirReq: data-element=R_CoCha_tqEfcAirReq.CoCha_tqEfcAirReq
          dr_Cha_tqMSRReq: data-element=R_Cha_tqMSRReq.Cha_tqMSRReq
          dr_TqSys_tqCkEfcAirFilExt: data-element=R_TqSys_tqCkEfcAirFilExt.TqSys_tqCkEfcAirFilExt
          dr_CoCha_tqEfcAirReqExt: data-element=R_CoCha_tqEfcAirReqExt.CoCha_tqEfcAirReqExt
          dr_TqSys_tqCkEfcFilExt: data-element=R_TqSys_tqCkEfcFilExt.TqSys_tqCkEfcFilExt
          dr_TqCha_tqAirTqIncReqExt: data-element=R_TqCha_tqAirTqIncReqExt.TqCha_tqAirTqIncReqExt
          dr_TqSys_tqCkEfcFil: data-element=R_TqSys_tqCkEfcFil.TqSys_tqCkEfcFil
          dr_CoPt_bSIP: data-element=R_CoPt_bSIP.CoPt_bSIP
          dr_CoPt_bAcvTqNCord: data-element=R_CoPt_bAcvTqNCord.CoPt_bAcvTqNCord
          dr_TqSys_tqEfcAirIdl: data-element=R_TqSys_tqEfcAirIdl.TqSys_tqEfcAirIdl
          dr_TqLimEM_tqLimEMExt: data-element=R_TqLimEM_tqLimEMExt.TqLimEM_tqLimEMExt
          dr_EngLim_tqCkEfcGBxLimCordEL2: data-element=R_EngLim_tqCkEfcGBxLimCordEL2.EngLim_tqCkEfcGBxLimCordEL2
          dr_TqSys_bTypFu: data-element=R_TqSys_bTypFu.TqSys_bTypFu
          dr_TqSys_stTypPwtCf: data-element=R_TqSys_stTypPwtCf.TqSys_stTypPwtCf
          dr_TqSys_tqEfcIdl: data-element=R_TqSys_tqEfcIdl.TqSys_tqEfcIdl
          dr_Cha_tqDynASRReq: data-element=R_Cha_tqDynASRReq.Cha_tqDynASRReq
          dr_CoVSCtl_tqSIPTar: data-element=R_CoVSCtl_tqSIPTar.CoVSCtl_tqSIPTar
          dr_TqCha_tqAirTqDecReq: data-element=R_TqCha_tqAirTqDecReq.TqCha_tqAirTqDecReq
          dr_TqCha_tqAirTqIncReq: data-element=R_TqCha_tqAirTqIncReq.TqCha_tqAirTqIncReq
          dr_TqCha_tqAirTqDecReqExt: data-element=R_TqCha_tqAirTqDecReqExt.TqCha_tqAirTqDecReqExt
          dr_EngLim_tqCkEfcATLimCordEL2: data-element=R_EngLim_tqCkEfcATLimCordEL2.EngLim_tqCkEfcATLimCordEL2
          dr_CoPt_bAcvTqMaxEstim: data-element=R_CoPt_bAcvTqMaxEstim.CoPt_bAcvTqMaxEstim
          dr_TqLimEM_tqLimEM: data-element=R_TqLimEM_tqLimEM.TqLimEM_tqLimEM
          dr_CoCha_tqEfcReq: data-element=R_CoCha_tqEfcReq.CoCha_tqEfcReq
          dr_CoCha_tqEfcReqExt: data-element=R_CoCha_tqEfcReqExt.CoCha_tqEfcReqExt
          dr_TqSys_tqCkEfcAirFil: data-element=R_TqSys_tqCkEfcAirFil.TqSys_tqCkEfcAirFil
          dr_TqCmp_tqCnvLoss: data-element=R_TqCmp_tqCnvLoss.TqCmp_tqCnvLoss
          dr_Ext_stTraTypCf: data-element=R_Ext_stTraTypCf.Ext_stTraTypCf
        7 x data send point:
          ds_CoPt_bDeacCllIt: data-element=P_CoPt_bDeacCllIt.CoPt_bDeacCllIt
          ds_CoPt_tqAirCord_tqGBx: data-element=P_CoPt_tqAirCord_tqGBx.CoPt_tqAirCord_tqGBx
          ds_CoPt_tqDrvFil: data-element=P_CoPt_tqDrvFil.CoPt_tqDrvFil
          ds_CoPt_tqCord_tqGBx: data-element=P_CoPt_tqCord_tqGBx.CoPt_tqCord_tqGBx
          ds_CoPt_tqDrvRaw: data-element=P_CoPt_tqDrvRaw.CoPt_tqDrvRaw
          ds_CoPt_tqAirDrvFil: data-element=P_CoPt_tqAirDrvFil.CoPt_tqAirDrvFil
          ds_CoPt_tqDrvRawTarGear: data-element=P_CoPt_tqDrvRawTarGear.CoPt_tqDrvRawTarGear
  swc implementation Imp_TraBVx: programming-language=C, behavior=IB_TraBVx
    code-descriptors:
      code CodeDescriptor: type=SRC
        39 x xfile:
          TraBVx_020_lut_c: url=TraBVx_020_lut.c
          TraBVx_030_TEV_fct_c: url=TraBVx_030_TEV_fct.c
          TraBVx_032_TEV_fct_h: url=TraBVx_032_TEV_fct.h
          TraBVx_028_calibrations_h: url=TraBVx_028_calibrations.h
          TraBVx_020_calibrations_c: url=TraBVx_020_calibrations.c
          TraBVx_018_lut_h: url=TraBVx_018_lut.h
          TraBVx_028_lut_c: url=TraBVx_028_lut.c
          TraBVx_018_calibrations_h: url=TraBVx_018_calibrations.h
          TraBVx_032_TEV_fct_c: url=TraBVx_032_TEV_fct.c
          TraBVx_030_calibrations_c: url=TraBVx_030_calibrations.c
          TraBVx_018_DRE_fct_h: url=TraBVx_018_DRE_fct.h
          TraBVx_020_DRE_fct_h: url=TraBVx_020_DRE_fct.h
          TraBVx_MemMap_h: url=TraBVx_MemMap.h
          TraBVx_032_calibrations_c: url=TraBVx_032_calibrations.c
          TraBVx_018_DRE_fct_c: url=TraBVx_018_DRE_fct.c
          TraBVx_020_lut_h: url=TraBVx_020_lut.h
          TraBVx_018_calibrations_c: url=TraBVx_018_calibrations.c
          TraBVx_h: url=TraBVx.h
          TraBVx_020_DRE_fct_c: url=TraBVx_020_DRE_fct.c
          TraBVx_030_TEV_fct_h: url=TraBVx_030_TEV_fct.h
          TraBVx_016_lut_c: url=TraBVx_016_lut.c
          TraBVx_028_calibrations_c: url=TraBVx_028_calibrations.c
          TraBVx_018_lut_c: url=TraBVx_018_lut.c
          TraBVx_028_TEV_fct_c: url=TraBVx_028_TEV_fct.c
          TraBVx_030_calibrations_h: url=TraBVx_030_calibrations.h
          TraBVx_030_lut_h: url=TraBVx_030_lut.h
          TraBVx_030_lut_c: url=TraBVx_030_lut.c
          TraBVx_020_calibrations_h: url=TraBVx_020_calibrations.h
          TraBVx_032_lut_c: url=TraBVx_032_lut.c
          TraBVx_016_DRE_fct_c: url=TraBVx_016_DRE_fct.c
          TraBVx_016_calibrations_c: url=TraBVx_016_calibrations.c
          TraBVx_028_TEV_fct_h: url=TraBVx_028_TEV_fct.h
          TraBVx_016_calibrations_h: url=TraBVx_016_calibrations.h
          TraBVx_c: url=TraBVx.c
          TraBVx_016_DRE_fct_h: url=TraBVx_016_DRE_fct.h
          TraBVx_028_lut_h: url=TraBVx_028_lut.h
          TraBVx_032_calibrations_h: url=TraBVx_032_calibrations.h
          TraBVx_032_lut_h: url=TraBVx_032_lut.h
          TraBVx_016_lut_h: url=TraBVx_016_lut.h
package /Components/SWC_TraBVx/TraBVx_IRVDatatypes
  boolean type DT_CoPt_bDeacCllNReg_irv: base-type=boolean
  boolean type DT_CoPt_bInhNCross_irv: base-type=boolean
  boolean type DT_CoPt_bVldAcvNReg_irv: base-type=boolean
  8 x integer type:
    DT_CoPt_nErrNReg_irv: base-type=int16, lower-limit=-32768, upper-limit=32767
    DT_CoPt_noTypPIDGain_irv: base-type=uint8, lower-limit=0, upper-limit=255
    DT_CoPt_stPhaGS_irv: base-type=uint8, lower-limit=0, upper-limit=255
    DT_CoPt_tqAirReqGBx: base-type=int16, lower-limit=-32768, upper-limit=32767
    DT_CoPt_tqGBxLossNReg_irv: base-type=int16, lower-limit=-32768, upper-limit=32767
    DT_CoPt_tqIdcNReg_irv: base-type=int16, lower-limit=-32768, upper-limit=32767
    DT_CoPt_tqIniNReg_irv: base-type=int16, lower-limit=-32768, upper-limit=32767
    DT_CoPt_tqReqGBx: base-type=int16, lower-limit=-32768, upper-limit=32767
